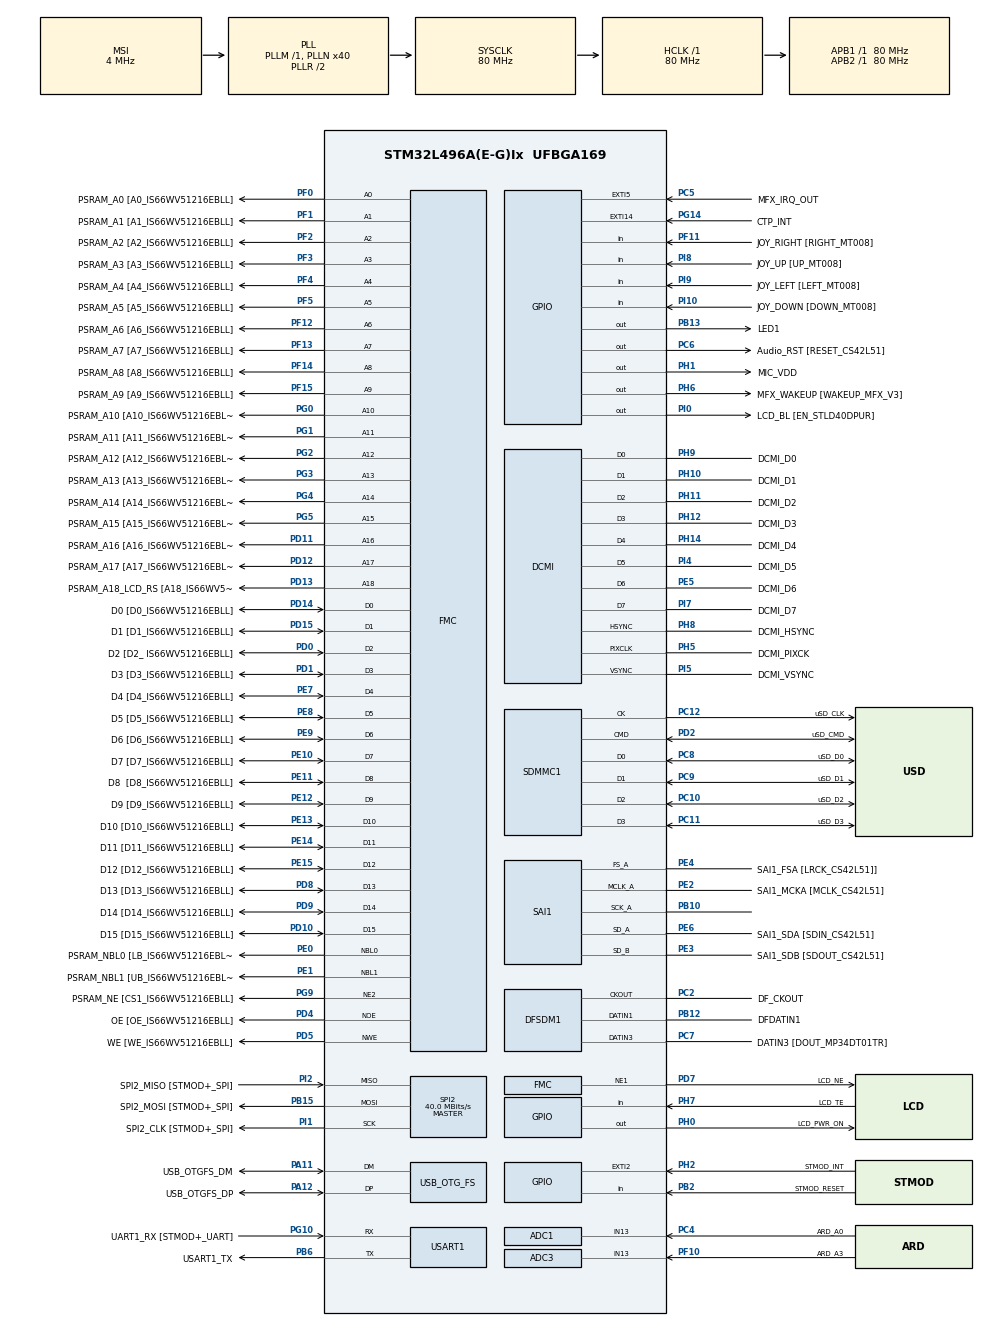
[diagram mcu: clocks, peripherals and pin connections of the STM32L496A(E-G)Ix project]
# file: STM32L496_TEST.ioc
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ADC1.Channel-0\#ChannelRegularConversion=ADC_CHANNEL_13
ADC1.NbrOfConversionFlag=1
ADC1.OffsetNumber-0\#ChannelRegularConversion=ADC_OFFSET_NONE
ADC1.Rank-0\#ChannelRegularConversion=1
ADC1.SamplingTime-0\#ChannelRegularConversion=ADC_SAMPLETIME_2CYCLES_5
ADC1.master=1
ADC3.Channel-0\#ChannelRegularConversion=ADC_CHANNEL_13
ADC3.NbrOfConversionFlag=1
ADC3.OffsetNumber-0\#ChannelRegularConversion=ADC_OFFSET_NONE
ADC3.Rank-0\#ChannelRegularConversion=1
ADC3.SamplingTime-0\#ChannelRegularConversion=ADC_SAMPLETIME_2CYCLES_5
ARM.CMSIS.5.8.0.CMSISJjCORE=true
ARM.CMSIS.5.8.0.CMSISJjDSP=Source
ARM.CMSIS.5.8.0.CMSISJjNNOoLib=true
DCMI.JPEGMode=DCMI_JPEG_DISABLE
Dma.Request0=SDMMC1_RX
Dma.Request1=SDMMC1_TX
Dma.SDMMC1_RX.0.Direction=DMA_PERIPH_TO_MEMORY
Dma.SDMMC1_RX.0.Instance=DMA2_Channel4
Dma.SDMMC1_RX.0.MemDataAlignment=DMA_MDATAALIGN_WORD
Dma.SDMMC1_RX.0.MemInc=DMA_MINC_ENABLE
Dma.SDMMC1_RX.0.Mode=DMA_NORMAL
Dma.SDMMC1_RX.0.PeriphDataAlignment=DMA_PDATAALIGN_WORD
Dma.SDMMC1_RX.0.PeriphInc=DMA_PINC_DISABLE
Dma.SDMMC1_RX.0.Priority=DMA_PRIORITY_LOW
Dma.SDMMC1_TX.1.Direction=DMA_MEMORY_TO_PERIPH
Dma.SDMMC1_TX.1.Instance=DMA2_Channel5
Dma.SDMMC1_TX.1.MemDataAlignment=DMA_MDATAALIGN_WORD
Dma.SDMMC1_TX.1.MemInc=DMA_MINC_ENABLE
Dma.SDMMC1_TX.1.Mode=DMA_NORMAL
Dma.SDMMC1_TX.1.PeriphDataAlignment=DMA_PDATAALIGN_WORD
Dma.SDMMC1_TX.1.PeriphInc=DMA_PINC_DISABLE
Dma.SDMMC1_TX.1.Priority=DMA_PRIORITY_LOW
FATFS.USE_DMA_CODE_SD=1
FATFS._USE_LFN=1
Mcu.Family=STM32L4
Mcu.Name=STM32L496A(E-G)Ix
Mcu.Package=UFBGA169
NVIC.DMA2_Channel4_IRQn=true\:5\:0\:true\:false\:true\:false\:true\:true
NVIC.DMA2_Channel5_IRQn=true\:5\:0\:true\:false\:true\:false\:true\:true
NVIC.OTG_FS_IRQn=true\:0\:0\:false\:false\:true\:true\:true\:true
NVIC.PriorityGroup=NVIC_PRIORITYGROUP_4
NVIC.SDMMC1_IRQn=true\:5\:0\:true\:false\:true\:true\:true\:true
NVIC.TIM5_IRQn=true\:0\:0\:false\:false\:true\:true\:true\:true
PA0.GPIO_Label=STMOD_PWM
PA0.Mode=SYS_WakeUp0
PA0.Signal=SYS_WKUP1
PA1.GPIO_Label=ARD_A4
PA1.Signal=ADCx_IN6
PA10.GPIO_Label=USB_OTGFS_ID
PA10.Signal=USB_OTG_FS_ID
PA11.GPIO_Label=USB_OTGFS_DM
PA11.Mode=Device_Only
PA11.Signal=USB_OTG_FS_DM
PA12.GPIO_Label=USB_OTGFS_DP
PA12.Mode=Device_Only
PA12.Signal=USB_OTG_FS_DP
PA13\ (JTMS/SWDIO).GPIO_Label=SWDIO
PA13\ (JTMS/SWDIO).Mode=Serial_Wire
PA13\ (JTMS/SWDIO).Signal=SYS_JTMS-SWDIO
PA14\ (JTCK/SWCLK).GPIO_Label=SWCLK
PA14\ (JTCK/SWCLK).Mode=Serial_Wire
PA14\ (JTCK/SWCLK).Signal=SYS_JTCK-SWCLK
PA15\ (JTDI).GPIO_Label=ARD_D10
PA15\ (JTDI).Signal=SPI1_NSS
PA2.GPIO_Label=USART2_TX
PA2.Signal=USART2_TX
PA3.GPIO_Label=QSPI_CLK [MX25R6435FM2IL0_SCLK]
PA3.Signal=QUADSPI_CLK
PA4.GPIO_Label=STMOD_ADC
PA4.Signal=ADCx_IN9
PA5.GPIO_Label=ARD_D13
PA5.Signal=SPI1_SCK
PA6.GPIO_Label=QSPI_BK1_IO3 [MX25R6435FM2IL0_SIO3]
PA6.Signal=QUADSPI_BK1_IO3
PA7.GPIO_Label=QSPI_BK1_IO2 [MX25R6435FM2IL0_SIO2]
PA7.Signal=QUADSPI_BK1_IO2
PA8.GPIO_Label=DCMI_CLK
PA8.Signal=LPTIM2_OUT
PA9.GPIO_Label=USB_OTGFS_VBUS
PA9.Signal=USB_OTG_FS_VBUS
PB0.GPIO_Label=QSPI_BK1_IO1 [MX25R6435FM2IL0_SIO1]
PB0.Signal=QUADSPI_BK1_IO1
PB1.GPIO_Label=QSPI_BK1_IO0 [MX25R6435FM2IL0_SIO0]
PB1.Signal=QUADSPI_BK1_IO0
PB10.Mode=SAI_A_MasterWithClock
PB10.Signal=SAI1_SCK_A
PB11.GPIO_Label=QSPI_BK1_NCS [MX25R6435FM2IL0_CS]
PB11.Signal=QUADSPI_BK1_NCS
PB12.GPIO_Label=DFDATIN1
PB12.Signal=S_DATAIN1DFSDM1
PB13.GPIO_Label=LED1
PB13.GPIO_ModeDefaultOutputPP=GPIO_MODE_OUTPUT_OD
PB13.GPIO_PuPd=GPIO_NOPULL
PB13.Signal=GPIO_Output
PB14.GPIO_Label=I2C2_SDA [CS42L51_SDA]
PB14.GPIO_Pu=GPIO_PULLUP
PB14.Signal=I2C2_SDA
PB15.GPIO_Label=SPI2_MOSI [STMOD+_SPI]
PB15.Mode=Full_Duplex_Master
PB15.Signal=SPI2_MOSI
PB2.GPIO_Label=STMOD_RESET
PB2.Signal=GPIO_Input
PB3\ (JTDO/TRACESWO).GPIO_Label=SWO
PB3\ (JTDO/TRACESWO).Signal=SYS_JTDO-SWO
PB4\ (NJTRST).GPIO_Label=ARD_D12
PB4\ (NJTRST).Signal=SPI1_MISO
PB5.GPIO_Label=ARD_D11
PB5.Signal=SPI1_MOSI
PB6.GPIO_Label=USART1_TX
PB6.Mode=Asynchronous
PB6.Signal=USART1_TX
PB7.GPIO_Label=I2C1_SDA
PB7.GPIO_Pu=GPIO_PULLUP
PB7.Signal=I2C1_SDA
PB8.GPIO_Label=I2C1_SCL
PB8.GPIO_Pu=GPIO_PULLUP
PB8.Signal=I2C1_SCL
PB9.GPIO_Label=ARD_D5
PB9.Signal=S_TIM4_CH4
PC0.GPIO_Label=ARD_A5
PC0.Signal=ADCx_IN1
PC1.Signal=ADCx_IN2
PC10.GPIO_Label=uSD_D2
PC10.GPIO_PuPd=GPIO_PULLUP
PC10.Mode=SD_4_bits_Wide_bus
PC10.Signal=SDMMC1_D2
PC11.GPIO_Label=uSD_D3
PC11.GPIO_PuPd=GPIO_PULLUP
PC11.Mode=SD_4_bits_Wide_bus
PC11.Signal=SDMMC1_D3
PC12.GPIO_Label=uSD_CLK
PC12.GPIO_PuPd=GPIO_PULLUP
PC12.Mode=SD_4_bits_Wide_bus
PC12.Signal=SDMMC1_CK
PC13.GPIO_Label=JOY_SEL [Selection_MT008]
PC13.Mode=SYS_WakeUp1
PC13.Signal=SYS_WKUP2
PC14-OSC32_IN\ (PC14).Mode=LSE-External-Clock-Source
PC14-OSC32_IN\ (PC14).Signal=RCC_OSC32_IN
PC15-OSC32_OUT\ (PC15).Signal=RCC_OSC32_OUT
PC2.GPIO_Label=DF_CKOUT
PC2.Signal=S_CKOUTDFSDM1
PC3.GPIO_Label=ARD_A2
PC3.Signal=ADCx_IN4
PC4.GPIO_Label=ARD_A0
PC4.Signal=ADCx_IN13
PC5.GPIO_Label=MFX_IRQ_OUT
PC5.Signal=GPXTI5
PC6.GPIO_Label=Audio_RST [RESET_CS42L51]
PC6.Signal=GPIO_Output
PC7.GPIO_Label=DATIN3 [DOUT_MP34DT01TR]
PC7.Signal=S_DATAIN3DFSDM1
PC8.GPIO_Label=uSD_D0
PC8.GPIO_PuPd=GPIO_PULLUP
PC8.Mode=SD_4_bits_Wide_bus
PC8.Signal=SDMMC1_D0
PC9.GPIO_Label=uSD_D1
PC9.GPIO_PuPd=GPIO_PULLUP
PC9.Mode=SD_4_bits_Wide_bus
PC9.Signal=SDMMC1_D1
PD0.GPIO_Label=D2 [D2_ IS66WV51216EBLL]
PD0.Signal=FMC_D2_DA2
PD1.GPIO_Label=D3 [D3_IS66WV51216EBLL]
PD1.Signal=FMC_D3_DA3
PD10.GPIO_Label=D15 [D15_IS66WV51216EBLL]
PD10.Signal=FMC_D15_DA15
PD11.GPIO_Label=PSRAM_A16 [A16_IS66WV51216EBLL]
PD11.Signal=FMC_A16_CLE
PD12.GPIO_Label=PSRAM_A17 [A17_IS66WV51216EBLL]
PD12.Signal=FMC_A17_ALE
PD13.GPIO_Label=PSRAM_A18_LCD_RS [A18_IS66WV51216EBLL]
PD13.Signal=FMC_A18
PD14.GPIO_Label=D0 [D0_IS66WV51216EBLL]
PD14.Signal=FMC_D0_DA0
PD15.GPIO_Label=D1 [D1_IS66WV51216EBLL]
PD15.Signal=FMC_D1_DA1
PD2.GPIO_Label=uSD_CMD
PD2.GPIO_PuPd=GPIO_PULLUP
PD2.Mode=SD_4_bits_Wide_bus
PD2.Signal=SDMMC1_CMD
PD4.GPIO_Label=OE [OE_IS66WV51216EBLL]
PD4.Signal=FMC_NOE
PD5.GPIO_Label=WE [WE_IS66WV51216EBLL]
PD5.Signal=FMC_NWE
PD6.GPIO_Label=USART2_RX
PD6.Signal=USART2_RX
PD7.GPIO_Label=LCD_NE
PD7.Mode=NorPsramChipSelect1_2
PD7.Signal=FMC_NE1
PD8.GPIO_Label=D13 [D13_IS66WV51216EBLL]
PD8.Signal=FMC_D13_DA13
PD9.GPIO_Label=D14 [D14_IS66WV51216EBLL]
PD9.Signal=FMC_D14_DA14
PE0.GPIO_Label=PSRAM_NBL0 [LB_IS66WV51216EBLL]
PE0.Signal=FMC_NBL0
PE1.GPIO_Label=PSRAM_NBL1 [UB_IS66WV51216EBLL]
PE1.Signal=FMC_NBL1
PE10.GPIO_Label=D7 [D7_IS66WV51216EBLL]
PE10.Signal=FMC_D7_DA7
PE11.GPIO_Label=D8  [D8_IS66WV51216EBLL]
PE11.Signal=FMC_D8_DA8
PE12.GPIO_Label=D9 [D9_IS66WV51216EBLL]
PE12.Signal=FMC_D9_DA9
PE13.GPIO_Label=D10 [D10_IS66WV51216EBLL]
PE13.Signal=FMC_D10_DA10
PE14.GPIO_Label=D11 [D11_IS66WV51216EBLL]
PE14.Signal=FMC_D11_DA11
PE15.GPIO_Label=D12 [D12_IS66WV51216EBLL]
PE15.Signal=FMC_D12_DA12
PE2.GPIO_Label=SAI1_MCKA [MCLK_CS42L51]
PE2.Mode=SAI_A_MasterWithClock
PE2.Signal=SAI1_MCLK_A
PE3.GPIO_Label=SAI1_SDB [SDOUT_CS42L51]
PE3.Mode=SAI_B_SyncSlave
PE3.Signal=SAI1_SD_B
PE4.GPIO_Label=SAI1_FSA [LRCK_CS42L51]]
PE4.Mode=SAI_A_MasterWithClock
PE4.Signal=SAI1_FS_A
PE5.GPIO_Label=DCMI_D6
PE5.Mode=Slave_8_bits_External_Synchro
PE5.Signal=DCMI_D6
PE6.GPIO_Label=SAI1_SDA [SDIN_CS42L51]
PE6.Mode=SAI_A_MasterWithClock
PE6.Signal=SAI1_SD_A
PE7.GPIO_Label=D4 [D4_IS66WV51216EBLL]
PE7.Signal=FMC_D4_DA4
PE8.GPIO_Label=D5 [D5_IS66WV51216EBLL]
PE8.Signal=FMC_D5_DA5
PE9.GPIO_Label=D6 [D6_IS66WV51216EBLL]
PE9.Signal=FMC_D6_DA6
PF0.GPIO_Label=PSRAM_A0 [A0_IS66WV51216EBLL]
PF0.Signal=FMC_A0
PF1.GPIO_Label=PSRAM_A1 [A1_IS66WV51216EBLL]
PF1.Signal=FMC_A1
PF10.GPIO_Label=ARD_A3
PF10.Mode=IN13-Single-Ended
PF10.Signal=ADC3_IN13
PF11.GPIO_Label=JOY_RIGHT [RIGHT_MT008]
PF11.GPIO_PuPd=GPIO_PULLDOWN
PF11.Signal=GPIO_Input
PF12.GPIO_Label=PSRAM_A6 [A6_IS66WV51216EBLL]
PF12.Signal=FMC_A6
PF13.GPIO_Label=PSRAM_A7 [A7_IS66WV51216EBLL]
PF13.Signal=FMC_A7
PF14.GPIO_Label=PSRAM_A8 [A8_IS66WV51216EBLL]
PF14.Signal=FMC_A8
PF15.GPIO_Label=PSRAM_A9 [A9_IS66WV51216EBLL]
PF15.Signal=FMC_A9
PF2.GPIO_Label=PSRAM_A2 [A2_IS66WV51216EBLL]
PF2.Signal=FMC_A2
PF3.GPIO_Label=PSRAM_A3 [A3_IS66WV51216EBLL]
PF3.Signal=FMC_A3
PF4.GPIO_Label=PSRAM_A4 [A4_IS66WV51216EBLL]
PF4.Signal=FMC_A4
PF5.GPIO_Label=PSRAM_A5 [A5_IS66WV51216EBLL]
PF5.Signal=FMC_A5
PG0.GPIO_Label=PSRAM_A10 [A10_IS66WV51216EBLL]
PG0.Signal=FMC_A10
PG1.GPIO_Label=PSRAM_A11 [A11_IS66WV51216EBLL]
PG1.Signal=FMC_A11
PG10.GPIO_Label=UART1_RX [STMOD+_UART]
PG10.Mode=Asynchronous
PG10.Signal=USART1_RX
PG11.GPIO_Label=UART1_CTS [STMOD+_UART]
PG11.Signal=USART1_CTS
PG12.GPIO_Label=UART1_RTS [STMOD+_UART]
PG12.Signal=USART1_RTS
PG14.GPIO_Label=CTP_INT
PG14.Signal=GPXTI14
PG2.GPIO_Label=PSRAM_A12 [A12_IS66WV51216EBLL]
PG2.Signal=FMC_A12
PG3.GPIO_Label=PSRAM_A13 [A13_IS66WV51216EBLL]
PG3.Signal=FMC_A13
PG4.GPIO_Label=PSRAM_A14 [A14_IS66WV51216EBLL]
PG4.Signal=FMC_A14
PG5.GPIO_Label=PSRAM_A15 [A15_IS66WV51216EBLL]
PG5.Signal=FMC_A15
PG7.GPIO_Label=ARD_D1
PG7.Signal=LPUART1_TX
PG8.GPIO_Label=ARD_D0
PG8.Signal=LPUART1_RX
PG9.GPIO_Label=PSRAM_NE [CS1_IS66WV51216EBLL]
PG9.Mode=NorPsramChipSelect2_1
PG9.Signal=FMC_NE2
PH0-OSC_IN\ (PH0).GPIO_Label=LCD_PWR_ON
PH0-OSC_IN\ (PH0).Signal=GPIO_Output
PH1-OSC_OUT\ (PH1).GPIO_Label=MIC_VDD
PH1-OSC_OUT\ (PH1).Signal=GPIO_Output
PH10.GPIO_Label=DCMI_D1
PH10.Mode=Slave_8_bits_External_Synchro
PH10.Signal=DCMI_D1
PH11.GPIO_Label=DCMI_D2
PH11.Mode=Slave_8_bits_External_Synchro
PH11.Signal=DCMI_D2
PH12.GPIO_Label=DCMI_D3
PH12.Mode=Slave_8_bits_External_Synchro
PH12.Signal=DCMI_D3
PH13.GPIO_Label=ARD_D9
PH13.Signal=TIM8_CH1N
PH14.GPIO_Label=DCMI_D4
PH14.Mode=Slave_8_bits_External_Synchro
PH14.Signal=DCMI_D4
PH15.GPIO_Label=ARD_D3
PH15.Signal=TIM8_CH3N
PH2.GPIO_Label=STMOD_INT
PH2.Signal=GPXTI2
PH4.GPIO_Label=I2C2_SCL [SCL_CS42L51]
PH4.GPIO_Pu=GPIO_PULLUP
PH4.Signal=I2C2_SCL
PH5.GPIO_Label=DCMI_PIXCK
PH5.Mode=Slave_8_bits_External_Synchro
PH5.Signal=DCMI_PIXCLK
PH6.GPIO_Label=MFX_WAKEUP [WAKEUP_MFX_V3]
PH6.Signal=GPIO_Output
PH7.GPIO_Label=LCD_TE
PH7.Signal=GPIO_Input
PH8.GPIO_Label=DCMI_HSYNC
PH8.Mode=Slave_8_bits_External_Synchro
PH8.Signal=DCMI_HSYNC
PH9.GPIO_Label=DCMI_D0
PH9.Mode=Slave_8_bits_External_Synchro
PH9.Signal=DCMI_D0
PI0.GPIO_Label=LCD_BL [EN_STLD40DPUR]
PI0.Signal=GPIO_Output
PI1.GPIO_Label=SPI2_CLK [STMOD+_SPI]
PI1.Mode=Full_Duplex_Master
PI1.Signal=SPI2_SCK
PI10.GPIO_Label=JOY_DOWN [DOWN_MT008]
PI10.GPIO_PuPd=GPIO_PULLDOWN
PI10.Signal=GPIO_Input
PI2.GPIO_Label=SPI2_MISO [STMOD+_SPI]
PI2.Mode=Full_Duplex_Master
PI2.Signal=SPI2_MISO
PI4.GPIO_Label=DCMI_D5
PI4.Mode=Slave_8_bits_External_Synchro
PI4.Signal=DCMI_D5
PI5.GPIO_Label=DCMI_VSYNC
PI5.Mode=Slave_8_bits_External_Synchro
PI5.Signal=DCMI_VSYNC
PI6.GPIO_Label=ARD_D6
PI6.Signal=S_TIM8_CH2
PI7.GPIO_Label=DCMI_D7
PI7.Mode=Slave_8_bits_External_Synchro
PI7.Signal=DCMI_D7
PI8.GPIO_Label=JOY_UP [UP_MT008]
PI8.GPIO_PuPd=GPIO_PULLDOWN
PI8.Signal=GPIO_Input
PI9.GPIO_Label=JOY_LEFT [LEFT_MT008]
PI9.GPIO_PuPd=GPIO_PULLDOWN
PI9.Signal=GPIO_Input
ProjectManager.HeapSize=0x200
ProjectManager.StackSize=0x400
ProjectManager.TargetToolchain=STM32CubeIDE
RCC.ADCFreq_Value=48000000
RCC.AHBFreq_Value=80000000
RCC.APB1Freq_Value=80000000
RCC.APB1TimFreq_Value=80000000
RCC.APB2Freq_Value=80000000
RCC.APB2TimFreq_Value=80000000
RCC.CortexFreq_Value=80000000
RCC.HCLKFreq_Value=80000000
RCC.HSE_VALUE=8000000
RCC.HSI48_VALUE=48000000
RCC.HSI_VALUE=16000000
RCC.MSI_VALUE=4000000
RCC.PLLN=40
RCC.PLLSAI1N=24
RCC.SYSCLKFreq_VALUE=80000000
RCC.SYSCLKSource=RCC_SYSCLKSOURCE_PLLCLK
RCC.USBFreq_Value=48000000
RCC.VCOOutputFreq_Value=160000000
SAI1.ErrorAudioFreq-SAI_A_MasterWithClock=-2.34 %
SAI1.Instance-SAI_A_MasterWithClock=SAI$Index_Block_A
SAI1.Instance-SAI_B_SyncSlave=SAI$Index_Block_B
SAI1.MClockEnable-SAI_A_MasterWithClock=SAI_MASTERCLOCK_ENABLE
SAI1.RealAudioFreq-SAI_A_MasterWithClock=187.5 KHz
SAI1.VirtualMode-SAI_A_MasterWithClock=VM_MASTER
SAI1.VirtualMode-SAI_B_SyncSlave=VM_SLAVE
SH.ADCx_IN1.0=ADC2_IN1
SH.ADCx_IN13.0=ADC1_IN13,IN13-Single-Ended
SH.ADCx_IN2.0=ADC2_IN2
SH.ADCx_IN4.0=ADC1_IN4
SH.ADCx_IN6.0=ADC2_IN6
SH.ADCx_IN9.0=ADC2_IN9
SH.FMC_A0.0=FMC_A0,18b-a1
SH.FMC_A1.0=FMC_A1,18b-a1
SH.FMC_A10.0=FMC_A10,18b-a1
SH.FMC_A11.0=FMC_A11,18b-a1
SH.FMC_A12.0=FMC_A12,18b-a1
SH.FMC_A13.0=FMC_A13,18b-a1
SH.FMC_A14.0=FMC_A14,18b-a1
SH.FMC_A15.0=FMC_A15,18b-a1
SH.FMC_A16_CLE.0=FMC_A16,18b-a1
SH.FMC_A17_ALE.0=FMC_A17,18b-a1
SH.FMC_A18.0=FMC_A18,A18_2
SH.FMC_A2.0=FMC_A2,18b-a1
SH.FMC_A3.0=FMC_A3,18b-a1
SH.FMC_A4.0=FMC_A4,18b-a1
SH.FMC_A5.0=FMC_A5,18b-a1
SH.FMC_A6.0=FMC_A6,18b-a1
SH.FMC_A7.0=FMC_A7,18b-a1
SH.FMC_A8.0=FMC_A8,18b-a1
SH.FMC_A9.0=FMC_A9,18b-a1
SH.FMC_D0_DA0.0=FMC_D0,16b-d1
SH.FMC_D0_DA0.1=FMC_D0,16b-d2
SH.FMC_D10_DA10.0=FMC_D10,16b-d1
SH.FMC_D10_DA10.1=FMC_D10,16b-d2
SH.FMC_D11_DA11.0=FMC_D11,16b-d1
SH.FMC_D11_DA11.1=FMC_D11,16b-d2
SH.FMC_D12_DA12.0=FMC_D12,16b-d1
SH.FMC_D12_DA12.1=FMC_D12,16b-d2
SH.FMC_D13_DA13.0=FMC_D13,16b-d1
SH.FMC_D13_DA13.1=FMC_D13,16b-d2
SH.FMC_D14_DA14.0=FMC_D14,16b-d1
SH.FMC_D14_DA14.1=FMC_D14,16b-d2
SH.FMC_D15_DA15.0=FMC_D15,16b-d1
SH.FMC_D15_DA15.1=FMC_D15,16b-d2
SH.FMC_D1_DA1.0=FMC_D1,16b-d1
SH.FMC_D1_DA1.1=FMC_D1,16b-d2
SH.FMC_D2_DA2.0=FMC_D2,16b-d1
SH.FMC_D2_DA2.1=FMC_D2,16b-d2
SH.FMC_D3_DA3.0=FMC_D3,16b-d1
SH.FMC_D3_DA3.1=FMC_D3,16b-d2
SH.FMC_D4_DA4.0=FMC_D4,16b-d1
SH.FMC_D4_DA4.1=FMC_D4,16b-d2
SH.FMC_D5_DA5.0=FMC_D5,16b-d1
SH.FMC_D5_DA5.1=FMC_D5,16b-d2
SH.FMC_D6_DA6.0=FMC_D6,16b-d1
SH.FMC_D6_DA6.1=FMC_D6,16b-d2
SH.FMC_D7_DA7.0=FMC_D7,16b-d1
SH.FMC_D7_DA7.1=FMC_D7,16b-d2
SH.FMC_D8_DA8.0=FMC_D8,16b-d1
SH.FMC_D8_DA8.1=FMC_D8,16b-d2
SH.FMC_D9_DA9.0=FMC_D9,16b-d1
SH.FMC_D9_DA9.1=FMC_D9,16b-d2
SH.FMC_NBL0.0=FMC_NBL0,2ByteEnable1
SH.FMC_NBL1.0=FMC_NBL1,2ByteEnable1
SH.FMC_NOE.0=FMC_NOE,Sram1
SH.FMC_NOE.1=FMC_NOE,Lcd2
SH.FMC_NWE.0=FMC_NWE,Sram1
SH.FMC_NWE.1=FMC_NWE,Lcd2
SH.S_CKOUTDFSDM1.0=DFSDM1_CKOUT,PDM_SPI_Input_from_ch23_and_Internal_Clock
SH.S_CKOUTDFSDM1.1=DFSDM1_CKOUT,PDM_SPI_input_from_ch1_and_internal_clock
SH.S_DATAIN1DFSDM1.0=DFSDM1_DATIN1,PDM_SPI_input_from_ch1_and_internal_clock
SH.S_DATAIN3DFSDM1.0=DFSDM1_DATIN3,PDM_SPI_Input_from_ch23_and_Internal_Clock
SH.S_TIM4_CH4.0=TIM4_CH4
SH.S_TIM8_CH2.0=TIM8_CH2
SPI2.CalculateBaudRate=40.0 MBits/s
SPI2.Direction=SPI_DIRECTION_2LINES
SPI2.Mode=SPI_MODE_MASTER
SPI2.VirtualType=VM_MASTER
TIM5.Period=0xffffffff-1
TIM5.Prescaler=1-1
TIM6.Period=65536-1
TIM6.Prescaler=80-1
USART1.VirtualMode-Asynchronous=VM_ASYNC
USB_DEVICE.CLASS_NAME_FS=CDC
USB_DEVICE.VirtualMode=Cdc
USB_DEVICE.VirtualModeFS=Cdc_FS
USB_OTG_FS.VirtualMode=Device_Only
VP_ARM.CMSIS_VS_CMSISJjCORE_5.5.0_5.8.0.Mode=CMSISJjCORE
VP_ARM.CMSIS_VS_CMSISJjDSP_1.9.0-dev_5.8.0.Mode=CMSISJjDSP
VP_ARM.CMSIS_VS_CMSISJjNNOoLib_3.0.0_5.8.0.Mode=CMSISJjNNOoLib
VP_FATFS_VS_SDIO.Mode=SDIO
VP_TIM5_VS_ClockSourceINT.Mode=Internal
VP_TIM6_VS_ClockSourceINT.Mode=Enable_Timer
VP_USB_DEVICE_VS_USB_DEVICE_CDC_FS.Mode=CDC_FS
board=STM32L496G-DISCO

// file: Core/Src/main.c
/* USER CODE BEGIN Header */
/**
  ******************************************************************************
  * @file           : main.c
  * @brief          : Main program body
  ******************************************************************************
  * @attention
  *
  * Copyright (c) 2023 STMicroelectronics.
  * All rights reserved.
  *
  * This software is licensed under terms that can be found in the LICENSE file
  * in the root directory of this software component.
  * If no LICENSE file comes with this software, it is provided AS-IS.
  *
  ******************************************************************************
  */
/* USER CODE END Header */
#include "main.h"
#include "fatfs.h"
#include "usb_device.h"

/* USER CODE BEGIN Includes */
#include <stdint.h>
#include <stdlib.h>
#include <stdio.h>
#include <assert.h>

#include "nnom.h"
#include "weights.h"
/* USER CODE END Includes */

/* USER CODE BEGIN PD */
extern volatile uint64_t SysTickCnt;
extern volatile uint64_t SysTickCnt1;
extern volatile uint64_t SysTickCnt2;
uint64_t TimerDelay=0;
uint64_t TimerCount;
uint64_t TimerCountSec;
//extern volatile uint64_t us_SysTickCnt;
//extern volatile uint64_t us_SysTickCnt1;
/* USER CODE END PD */

ADC_HandleTypeDef hadc1;
ADC_HandleTypeDef hadc3;

DCMI_HandleTypeDef hdcmi;

DFSDM_Channel_HandleTypeDef hdfsdm1_channel1;
DFSDM_Channel_HandleTypeDef hdfsdm1_channel2;

SAI_HandleTypeDef hsai_BlockA1;
SAI_HandleTypeDef hsai_BlockB1;

SD_HandleTypeDef hsd1;
DMA_HandleTypeDef hdma_sdmmc1_rx;
DMA_HandleTypeDef hdma_sdmmc1_tx;

SPI_HandleTypeDef hspi2;

TIM_HandleTypeDef htim5;
TIM_HandleTypeDef htim6;

UART_HandleTypeDef huart1;

SRAM_HandleTypeDef hsram1;
SRAM_HandleTypeDef hsram2;

/* USER CODE BEGIN PV */
//void f_opendir_scan(void);
/* USER CODE END PV */

void SystemClock_Config(void);
void PeriphCommonClock_Config(void);
static void MX_GPIO_Init(void);
static void MX_DMA_Init(void);
static void MX_ADC1_Init(void);
static void MX_ADC3_Init(void);
static void MX_DCMI_Init(void);
static void MX_DFSDM1_Init(void);
static void MX_FMC_Init(void);
static void MX_USART1_UART_Init(void);
static void MX_SAI1_Init(void);
static void MX_SDMMC1_SD_Init(void);
static void MX_SPI2_Init(void);
static void MX_TIM6_Init(void);
static void MX_TIM5_Init(void);

/* USER CODE BEGIN 0 */
/*
void HAL_TIM_PeriodElapsedCallback(TIM_HandleTypeDef *htim)
{

	if(htim->Instance == TIM6)
	{
		if(TimerCount < 5000000)
		{
			TimerCount++;
		}
		else
		{
#if 0
			if(TimerCountSec < 60)
			{
				TimerCountSec++;
			}
			else
			{
				TimerCountSec=0;
			}
#endif
			TimerCount=0;
		}
	}
}
*/
int8_t* load(const char* file, size_t * size)
{
	size_t sz;
	FILE* fp = fopen(file,"rb");
	int8_t* input;
	assert(fp);
	fseek(fp, 0, SEEK_END);
	sz = ftell(fp);
	fseek(fp, 0, SEEK_SET);
	input = malloc(sz);
	fread(input, 1, sz, fp);
	fclose(fp);
	*size = sz;
	return input;
}

nnom_status_t callback(nnom_model_t* m, nnom_layer_t* layer)
{
	float scale = 1 << (layer->out->tensor->q_dec[0]);
	printf("\nOutput of Layer %s", default_layer_names[layer->type]);
	for (int i = 0; i < tensor_size(layer->out->tensor); i++)
	{
		if (i % 16 == 0)
			printf("\n");
		//printf("%f ", (float)((int8_t*)layer->out->tensor->p_data)[i] / scale);
	}
	printf("\n");
	return NN_SUCCESS;
}

/* USER CODE END 0 */

int main(void)
{
  /* USER CODE BEGIN 1 */
	uint64_t sine_input_data[400]=
			{
			 2.08695419, 0.76689931, 4.74582312, 5.05426909, 6.25972379, 5.17592351,
			 5.04563954, 2.70270019, 3.99913156, 5.98756371, 1.19539429, 3.28134257,
			 4.83127744, 3.65830856, 2.56685459, 5.54898327, 0.08833249, 0.56087708,
			 0.52861911, 5.09026597, 2.44528008, 5.73465215, 6.11904136, 2.80423079,
			 3.14940047, 3.63168313, 5.6821393,  0.57851344, 4.07710848, 3.54048319,
			 3.11324864, 2.10204613, 3.87680897, 0.19928605, 2.69465816, 0.22969943,
			 3.2490809, 3.7164528,  3.43202967, 2.04771038, 4.71435523, 3.12718626,
			 5.99622483, 6.26340629, 0.73648756, 0.780399,   6.02199553, 5.87205802,
			 4.45601254, 5.06354697, 4.78286746, 4.72836316, 1.59432706, 5.40692325,
			 1.22285658, 4.09214892, 4.64688536, 0.69933188, 5.71745025, 2.20655855,
			 4.33961395, 3.12272388, 4.72167151, 3.7150221,  5.6648941,  5.46039667,
			 2.77459441, 0.550436,   1.53303783, 3.52287725, 4.0653286,  4.36009327,
			 0.34010971, 2.44585525, 1.0348866,  5.33742292, 3.32143552, 3.33726546,
			 3.49536546, 2.24441524, 5.1390628,  5.49069287, 2.42088815, 0.90763034,
			 6.23429342, 0.15590885, 1.62910138, 3.14691749, 0.19715427, 0.42467694,
			 0.724386,   0.17056014, 3.29771079, 2.76921085, 1.62946275, 5.16783221,
			 0.80726899, 5.2280378,  1.81096906, 5.94610609, 4.84921627, 2.87473706,
			 5.8737587,  3.86788732, 1.2601702,  3.75132209, 1.24127618, 5.3913218,
			 1.5498286,  1.91143653, 0.63133646, 4.99938901, 0.49256017, 0.04035357,
			 5.6022348,  4.92948964, 5.65896911, 2.54951337, 2.67772437, 1.41867595,
			 3.99107708, 5.88654158, 3.88043218, 1.73779883, 5.10445431, 4.71479072,
			 0.73709591, 2.890005,   5.82162277, 0.24970332, 1.46252155, 5.29140275,
			 1.00074824, 3.01055499, 4.72678514, 3.32773414, 2.68666938, 4.46329594,
			 1.74474435, 2.29807342, 1.98501637, 2.46272018, 1.6153572,  2.59601391,
			 3.46666425, 5.63477438, 5.38232322, 1.67568923, 4.90026508, 1.75509981,
			 0.8844397,  5.73421103, 3.00028104, 3.31121815, 3.40114173, 0.2158798,
			 4.21723394, 3.0450399,  5.0505918,  4.07993413, 5.76991797, 0.03692868,
			 1.78871852, 2.06750289, 6.17315554, 0.41259688, 6.27580458, 3.31359511,
			 0.75584901, 0.77755006, 4.60445792, 2.79901728, 4.89211283, 4.51065309,
			 5.9556905,  1.04764683, 5.9245,     6.09746461, 0.67397198, 1.1175135,
			 0.27154077, 5.11226692, 0.95974585, 3.99382931, 3.01374228, 4.43766436,
			 4.9349161,  1.8536068,  2.81799255, 3.86591664, 3.71580724, 3.85324266,
			 3.65884674, 1.09280759, 3.51361338, 3.43296269, 0.276919,   0.70406377,
			 2.0265911,  1.23010984, 5.8723954,  5.57306316, 5.96544788, 4.5161241,
			 0.38560253, 1.05943098, 0.69713181, 1.35469022, 6.18105899, 5.50940501,
			 1.30293693, 0.5740297,  3.16573378, 1.52456956, 5.856283,   1.44380873,
			 4.58958354, 2.75357767, 3.38436842, 0.50722714, 5.65793132, 5.36222335,
			 4.29809155, 3.77912918, 5.0750548,  2.1628121,  0.46299865, 5.4858977,
			 4.07345295, 2.74685508, 3.22548635, 4.1514482,  0.03282755, 4.29765143,
			 1.11005891, 5.53483601, 3.20034811, 4.43732275, 5.54329779, 5.09172381,
			 1.87488243, 2.40444571, 2.77523744, 1.88837785, 0.35725745, 1.9903032,
			 1.98847203, 5.15257429, 5.23198119, 4.01861693, 1.01494732, 4.58564252,
			 5.49813942, 1.44230306, 3.3950008,  4.5575466,  2.1262126,  0.18657707,
			 1.80067403, 1.75972771, 2.40092871, 5.27486983, 3.62027504, 0.94121215,
			 4.24400976, 5.71093421, 3.33695234, 4.69042588, 4.6679446,  2.22999369,
			 3.04629233, 5.05546414, 6.23539512, 6.12784717, 4.76898606, 3.40453647,
			 4.18971958, 3.45977306, 5.33601224, 3.04373973, 2.09230867, 3.3597323,
			 4.2758165,  0.32494225, 1.08188177, 4.83807308, 6.12270297, 1.63917385,
			 0.05754941, 2.75779713, 2.56369735, 5.87874567, 0.11481112, 4.71573081,
			 1.06660722, 4.6480726,  2.1956989,  4.01952579, 5.18644456, 1.73525091,
			 4.13652427, 3.29216507, 1.81250605, 0.56569308, 2.27930236, 4.63858324,
			 5.96000597, 2.89179211, 4.88844215, 5.02268595, 5.85444001, 0.69439757,
			 5.05325718, 4.01808686, 1.11056002, 1.31843526, 3.92501732, 2.8849584,
			 3.78206903, 4.35851701, 4.55138129, 2.79028265, 3.12955137, 0.99998988,
			 1.28558634, 1.09003759, 5.35965953, 0.0670564,  0.37559138, 5.6332237,
			 1.6602608,  5.45714994, 1.88564882, 2.15390808, 2.50313823, 2.17726969,
			 3.2858739,  2.6412539,  2.29335861, 0.49016144, 3.64283181, 5.0059637,
			 4.07754492, 3.40703553, 3.8940697,  0.24084188, 2.5357001, 2.88979379,
			 3.09579139, 1.68811179, 1.19372458, 5.43472717, 0.16966966, 3.81456796,
			 1.43662181, 1.80431179, 2.01450516, 5.32662936, 1.46671327, 1.87310498,
			 0.88970747, 2.14186225, 3.22437468, 5.90339597, 2.29966888, 4.36749354,
			 0.26064666, 4.34127616, 4.18827682, 0.73445369, 0.1509077,  1.00256865,
			 4.99012329, 2.16234692, 2.3329883,  1.53013353, 4.43697189, 2.87249533,
			 3.96619262, 1.56197448, 0.70853612, 4.49769003, 4.17144703, 5.8445012,
			 3.89486767, 0.02230128, 2.61849801, 6.16805925, 5.07065454, 2.17824695,
			 1.90748733, 5.54388068, 3.9275137,  3.29888327, 6.24196832, 1.98646822,
			 2.14897505, 2.20384449, 3.55629195, 2.24916268};

	unsigned char input_data_third[7968] =
	{
			7,	2,	1,	0,	4,	1,	4,	9,	5,	9,	0,	6,	9,	0,	1,	5,	0,	0,	0,	0,	0,	0,	0,	0,	0,	0,	0,	0,
			0,	0,	0,	0,	0,	0,	0,	0,	0,	0,	0,	0,	0,	0,	0,	0,	0,	0,	0,	0,	0,	0,	0,	0,	0,	0,	0,	0,
			0,	0,	0,	0,	0,	0,	0,	0,	0,	0,	0,	0,	0,	0,	0,	0,	0,	0,	0,	0,	0,	0,	0,	0,	0,	0,	0,	0,
			0,	0,	0,	0,	0,	0,	0,	0,	0,	0,	0,	0,	0,	0,	0,	0,	0,	0,	0,	0,	0,	0,	0,	0,	0,	0,	0,	0,
			0,	0,	0,	0,	0,	0,	0,	0,	0,	0,	0,	0,	0,	0,	0,	0,

			0,	0,	0,	0,	0,	0,	0,	0,	0,	0,	0,	0,	0,	0,	0,	0,	0,	0,	0,	0,	0,	0,	0,	0,	0,	0,	0,	0,
			0,	0,	0,	0,	0,	0,	0,	0,	0,	0,	0,	0,	0,	0,	0,	0,	0,	0,	0,	0,	0,	0,	0,	0,	0,	0,	0,	0,
			0,	0,	0,	0,	0,	0,	0,	0,	0,	0,	0,	0,	0,	0,	0,	0,	0,	0,	0,	0,	0,	0,	0,	0,	0,	0,	0,	0,
			0,	0,	0,	0,	0,	0,	0,	0,	0,	0,	0,	0,	0,	0,	0,	0,	0,	0,	0,	0,	0,	0,	0,	0,	0,	0,	0,	0,
			0,	0,	0,	0,	0,	0,	0,	0,	0,	0,	0,	0,	0,	0,	0,	0,	0,	0,	0,	0,	0,	0,	0,	0,	0,	0,	0,	0,
			0,	0,	0,	0,	0,	0,	0,	0,	0,	0,	0,	0,	0,	0,	0,	0,	0,	0,	0,	0,	0,	0,	0,	0,	0,	0,	0,	0,
			0,	0,	0,	0,	0,	0,	0,	0,	0,	0,	0,	0,	0,	0,	0,	0,	0,	0,	0,	0,	0,	0,	0,	0,	0,	0,	0,	0,
			0,	0,	0,	0,	0,	0,	42,	92,	79,	75,	30,	18,	0,	0,	0,	0,	0,	0,	0,	0,	0,	0,	0,	0,	0,	0,	0,	0,
			0,	0,	0,	0,	0,	0,	111,	127,	127,	127,	127,	120,	99,	99,	99,	99,	99,	99,	99,	99,	85,	26,	0,	0,	0,	0,	0,	0,
			0,	0,	0,	0,	0,	0,	33,	57,	36,	57,	81,	113,	127,	112,	127,	127,	127,	125,	114,	127,	127,	70,	0,	0,	0,	0,	0,	0,
			0,	0,	0,	0,	0,	0,	0,	0,	0,	0,	0,	8,	33,	7,	33,	33,	33,	29,	10,	118,	127,	53,	0,	0,	0,	0,	0,	0,
			0,	0,	0,	0,	0,	0,	0,	0,	0,	0,	0,	0,	0,	0,	0,	0,	0,	0,	41,	126,	104,	9,	0,	0,	0,	0,	0,	0,
			0,	0,	0,	0,	0,	0,	0,	0,	0,	0,	0,	0,	0,	0,	0,	0,	0,	11,	116,	127,	41,	0,	0,	0,	0,	0,	0,	0,
			0,	0,	0,	0,	0,	0,	0,	0,	0,	0,	0,	0,	0,	0,	0,	0,	0,	64,	127,	119,	22,	0,	0,	0,	0,	0,	0,	0,
			0,	0,	0,	0,	0,	0,	0,	0,	0,	0,	0,	0,	0,	0,	0,	0,	29,	124,	127,	31,	0,	0,	0,	0,	0,	0,	0,	0,
			0,	0,	0,	0,	0,	0,	0,	0,	0,	0,	0,	0,	0,	0,	0,	0,	66,	127,	93,	2,	0,	0,	0,	0,	0,	0,	0,	0,
			0,	0,	0,	0,	0,	0,	0,	0,	0,	0,	0,	0,	0,	0,	0,	4,	102,	124,	29,	0,	0,	0,	0,	0,	0,	0,	0,	0,
			0,	0,	0,	0,	0,	0,	0,	0,	0,	0,	0,	0,	0,	0,	0,	63,	127,	91,	0,	0,	0,	0,	0,	0,	0,	0,	0,	0,
			0,	0,	0,	0,	0,	0,	0,	0,	0,	0,	0,	0,	0,	0,	37,	125,	120,	28,	0,	0,	0,	0,	0,	0,	0,	0,	0,	0,
			0,	0,	0,	0,	0,	0,	0,	0,	0,	0,	0,	0,	0,	9,	110,	127,	83,	0,	0,	0,	0,	0,	0,	0,	0,	0,	0,	0,
			0,	0,	0,	0,	0,	0,	0,	0,	0,	0,	0,	0,	1,	101,	127,	109,	17,	0,	0,	0,	0,	0,	0,	0,	0,	0,	0,	0,
			0,	0,	0,	0,	0,	0,	0,	0,	0,	0,	0,	0,	19,	127,	127,	38,	0,	0,	0,	0,	0,	0,	0,	0,	0,	0,	0,	0,
			0,	0,	0,	0,	0,	0,	0,	0,	0,	0,	0,	15,	112,	127,	57,	0,	0,	0,	0,	0,	0,	0,	0,	0,	0,	0,	0,	0,
			0,	0,	0,	0,	0,	0,	0,	0,	0,	0,	0,	66,	127,	127,	26,	0,	0,	0,	0,	0,	0,	0,	0,	0,	0,	0,	0,	0,
			0,	0,	0,	0,	0,	0,	0,	0,	0,	0,	30,	121,	127,	127,	26,	0,	0,	0,	0,	0,	0,	0,	0,	0,	0,	0,	0,	0,
			0,	0,	0,	0,	0,	0,	0,	0,	0,	0,	60,	127,	127,	109,	20,	0,	0,	0,	0,	0,	0,	0,	0,	0,	0,	0,	0,	0,
			0,	0,	0,	0,	0,	0,	0,	0,	0,	0,	60,	127,	103,	9,	0,	0,	0,	0,	0,	0,	0,	0,	0,	0,	0,	0,	0,	0,
			0,	0,	0,	0,	0,	0,	0,	0,	0,	0,	0,	0,	0,	0,	0,	0,	0,	0,	0,	0,	0,	0,	0,	0,	0,	0,	0,	0,

			0,	0,	0,	0,	0,	0,	0,	0,	0,	0,	0,	0,	0,	0,	0,	0,	0,	0,	0,	0,	0,	0,	0,	0,	0,	0,	0,	0,
			0,	0,	0,	0,	0,	0,	0,	0,	0,	0,	0,	0,	0,	0,	0,	0,	0,	0,	0,	0,	0,	0,	0,	0,	0,	0,	0,	0,
			0,	0,	0,	0,	0,	0,	0,	0,	0,	0,	0,	0,	0,	0,	0,	0,	0,	0,	0,	0,	0,	0,	0,	0,	0,	0,	0,	0,
			0,	0,	0,	0,	0,	0,	0,	0,	0,	0,	58,	62,	85,	127,	127,	75,	46,	0,	0,	0,	0,	0,	0,	0,	0,	0,	0,	0,
			0,	0,	0,	0,	0,	0,	0,	0,	0,	84,	126,	126,	126,	126,	126,	126,	109,	15,	0,	0,	0,	0,	0,	0,	0,	0,	0,	0,
			0,	0,	0,	0,	0,	0,	0,	0,	84,	126,	126,	126,	106,	71,	88,	126,	126,	61,	0,	0,	0,	0,	0,	0,	0,	0,	0,	0,
			0,	0,	0,	0,	0,	0,	0,	26,	125,	126,	105,	16,	6,	0,	3,	103,	126,	70,	0,	0,	0,	0,	0,	0,	0,	0,	0,	0,
			0,	0,	0,	0,	0,	0,	0,	38,	125,	105,	12,	0,	0,	0,	61,	124,	126,	32,	0,	0,	0,	0,	0,	0,	0,	0,	0,	0,
			0,	0,	0,	0,	0,	0,	0,	0,	15,	9,	0,	0,	0,	0,	104,	126,	126,	32,	0,	0,	0,	0,	0,	0,	0,	0,	0,	0,
			0,	0,	0,	0,	0,	0,	0,	0,	0,	0,	0,	0,	0,	58,	123,	126,	99,	5,	0,	0,	0,	0,	0,	0,	0,	0,	0,	0,
			0,	0,	0,	0,	0,	0,	0,	0,	0,	0,	0,	0,	38,	123,	126,	115,	31,	0,	0,	0,	0,	0,	0,	0,	0,	0,	0,	0,
			0,	0,	0,	0,	0,	0,	0,	0,	0,	0,	0,	0,	64,	126,	126,	72,	0,	0,	0,	0,	0,	0,	0,	0,	0,	0,	0,	0,
			0,	0,	0,	0,	0,	0,	0,	0,	0,	0,	0,	88,	123,	126,	79,	6,	0,	0,	0,	0,	0,	0,	0,	0,	0,	0,	0,	0,
			0,	0,	0,	0,	0,	0,	0,	0,	0,	0,	12,	117,	126,	116,	17,	0,	0,	0,	0,	0,	0,	0,	0,	0,	0,	0,	0,	0,
			0,	0,	0,	0,	0,	0,	0,	0,	0,	0,	99,	126,	126,	70,	0,	0,	0,	0,	0,	0,	0,	0,	0,	0,	0,	0,	0,	0,
			0,	0,	0,	0,	0,	0,	0,	0,	0,	39,	124,	126,	94,	6,	0,	0,	0,	0,	0,	0,	0,	0,	0,	0,	0,	0,	0,	0,
			0,	0,	0,	0,	0,	0,	0,	0,	9,	100,	126,	126,	70,	0,	0,	0,	0,	0,	0,	0,	0,	0,	0,	0,	0,	0,	0,	0,
			0,	0,	0,	0,	0,	0,	0,	0,	67,	126,	126,	86,	6,	0,	0,	0,	0,	0,	0,	0,	0,	0,	0,	0,	0,	0,	0,	0,
			0,	0,	0,	0,	0,	0,	0,	0,	124,	126,	126,	12,	0,	0,	0,	0,	0,	0,	0,	0,	0,	0,	0,	0,	0,	0,	0,	0,
			0,	0,	0,	0,	0,	0,	0,	0,	124,	126,	126,	21,	10,	10,	10,	10,	2,	0,	2,	10,	10,	18,	75,	75,	75,	73,	5,	0,
			0,	0,	0,	0,	0,	0,	0,	0,	124,	126,	126,	126,	126,	126,	126,	126,	84,	71,	83,	126,	126,	126,	126,	126,	126,	126,	61,	0,
			0,	0,	0,	0,	0,	0,	0,	0,	87,	126,	126,	126,	126,	126,	126,	126,	126,	126,	126,	126,	124,	123,	123,	84,	58,	58,	28,	0,
			0,	0,	0,	0,	0,	0,	0,	0,	0,	59,	61,	61,	61,	83,	126,	126,	126,	77,	61,	61,	20,	0,	0,	0,	0,	0,	0,	0,
			0,	0,	0,	0,	0,	0,	0,	0,	0,	0,	0,	0,	0,	0,	0,	0,	0,	0,	0,	0,	0,	0,	0,	0,	0,	0,	0,	0,
			0,	0,	0,	0,	0,	0,	0,	0,	0,	0,	0,	0,	0,	0,	0,	0,	0,	0,	0,	0,	0,	0,	0,	0,	0,	0,	0,	0,
			0,	0,	0,	0,	0,	0,	0,	0,	0,	0,	0,	0,	0,	0,	0,	0,	0,	0,	0,	0,	0,	0,	0,	0,	0,	0,	0,	0,
			0,	0,	0,	0,	0,	0,	0,	0,	0,	0,	0,	0,	0,	0,	0,	0,	0,	0,	0,	0,	0,	0,	0,	0,	0,	0,	0,	0,
			0,	0,	0,	0,	0,	0,	0,	0,	0,	0,	0,	0,	0,	0,	0,	0,	0,	0,	0,	0,	0,	0,	0,	0,	0,	0,	0,	0,

			0,	0,	0,	0,	0,	0,	0,	0,	0,	0,	0,	0,	0,	0,	0,	0,	0,	0,	0,	0,	0,	0,	0,	0,	0,	0,	0,	0,
			0,	0,	0,	0,	0,	0,	0,	0,	0,	0,	0,	0,	0,	0,	0,	0,	0,	0,	0,	0,	0,	0,	0,	0,	0,	0,	0,	0,
			0,	0,	0,	0,	0,	0,	0,	0,	0,	0,	0,	0,	0,	0,	0,	0,	0,	0,	0,	0,	0,	0,	0,	0,	0,	0,	0,	0,
			0,	0,	0,	0,	0,	0,	0,	0,	0,	0,	0,	0,	0,	0,	0,	0,	0,	0,	0,	0,	0,	0,	0,	0,	0,	0,	0,	0,
			0,	0,	0,	0,	0,	0,	0,	0,	0,	0,	0,	0,	0,	0,	0,	0,	19,	127,	54,	0,	0,	0,	0,	0,	0,	0,	0,	0,
			0,	0,	0,	0,	0,	0,	0,	0,	0,	0,	0,	0,	0,	0,	0,	0,	43,	126,	41,	0,	0,	0,	0,	0,	0,	0,	0,	0,
			0,	0,	0,	0,	0,	0,	0,	0,	0,	0,	0,	0,	0,	0,	0,	0,	67,	120,	0,	0,	0,	0,	0,	0,	0,	0,	0,	0,
			0,	0,	0,	0,	0,	0,	0,	0,	0,	0,	0,	0,	0,	0,	0,	22,	122,	75,	0,	0,	0,	0,	0,	0,	0,	0,	0,	0,
			0,	0,	0,	0,	0,	0,	0,	0,	0,	0,	0,	0,	0,	0,	0,	42,	127,	31,	0,	0,	0,	0,	0,	0,	0,	0,	0,	0,
			0,	0,	0,	0,	0,	0,	0,	0,	0,	0,	0,	0,	0,	0,	0,	101,	111,	5,	0,	0,	0,	0,	0,	0,	0,	0,	0,	0,
			0,	0,	0,	0,	0,	0,	0,	0,	0,	0,	0,	0,	0,	0,	16,	127,	108,	0,	0,	0,	0,	0,	0,	0,	0,	0,	0,	0,
			0,	0,	0,	0,	0,	0,	0,	0,	0,	0,	0,	0,	0,	0,	47,	127,	97,	0,	0,	0,	0,	0,	0,	0,	0,	0,	0,	0,
			0,	0,	0,	0,	0,	0,	0,	0,	0,	0,	0,	0,	0,	0,	70,	127,	38,	0,	0,	0,	0,	0,	0,	0,	0,	0,	0,	0,
			0,	0,	0,	0,	0,	0,	0,	0,	0,	0,	0,	0,	0,	28,	118,	102,	4,	0,	0,	0,	0,	0,	0,	0,	0,	0,	0,	0,
			0,	0,	0,	0,	0,	0,	0,	0,	0,	0,	0,	0,	0,	62,	127,	82,	0,	0,	0,	0,	0,	0,	0,	0,	0,	0,	0,	0,
			0,	0,	0,	0,	0,	0,	0,	0,	0,	0,	0,	0,	0,	85,	127,	40,	0,	0,	0,	0,	0,	0,	0,	0,	0,	0,	0,	0,
			0,	0,	0,	0,	0,	0,	0,	0,	0,	0,	0,	0,	12,	116,	107,	0,	0,	0,	0,	0,	0,	0,	0,	0,	0,	0,	0,	0,
			0,	0,	0,	0,	0,	0,	0,	0,	0,	0,	0,	0,	60,	127,	79,	0,	0,	0,	0,	0,	0,	0,	0,	0,	0,	0,	0,	0,
			0,	0,	0,	0,	0,	0,	0,	0,	0,	0,	0,	0,	75,	127,	71,	0,	0,	0,	0,	0,	0,	0,	0,	0,	0,	0,	0,	0,
			0,	0,	0,	0,	0,	0,	0,	0,	0,	0,	0,	0,	114,	127,	33,	0,	0,	0,	0,	0,	0,	0,	0,	0,	0,	0,	0,	0,
			0,	0,	0,	0,	0,	0,	0,	0,	0,	0,	0,	30,	125,	127,	33,	0,	0,	0,	0,	0,	0,	0,	0,	0,	0,	0,	0,	0,
			0,	0,	0,	0,	0,	0,	0,	0,	0,	0,	0,	70,	127,	102,	1,	0,	0,	0,	0,	0,	0,	0,	0,	0,	0,	0,	0,	0,
			0,	0,	0,	0,	0,	0,	0,	0,	0,	0,	5,	107,	127,	60,	0,	0,	0,	0,	0,	0,	0,	0,	0,	0,	0,	0,	0,	0,
			0,	0,	0,	0,	0,	0,	0,	0,	0,	0,	2,	99,	88,	5,	0,	0,	0,	0,	0,	0,	0,	0,	0,	0,	0,	0,	0,	0,
			0,	0,	0,	0,	0,	0,	0,	0,	0,	0,	0,	0,	0,	0,	0,	0,	0,	0,	0,	0,	0,	0,	0,	0,	0,	0,	0,	0,
			0,	0,	0,	0,	0,	0,	0,	0,	0,	0,	0,	0,	0,	0,	0,	0,	0,	0,	0,	0,	0,	0,	0,	0,	0,	0,	0,	0,
			0,	0,	0,	0,	0,	0,	0,	0,	0,	0,	0,	0,	0,	0,	0,	0,	0,	0,	0,	0,	0,	0,	0,	0,	0,	0,	0,	0,
			0,	0,	0,	0,	0,	0,	0,	0,	0,	0,	0,	0,	0,	0,	0,	0,	0,	0,	0,	0,	0,	0,	0,	0,	0,	0,	0,	0,

			0,	0,	0,	0,	0,	0,	0,	0,	0,	0,	0,	0,	0,	0,	0,	0,	0,	0,	0,	0,	0,	0,	0,	0,	0,	0,	0,	0,
			0,	0,	0,	0,	0,	0,	0,	0,	0,	0,	0,	0,	0,	0,	0,	0,	0,	0,	0,	0,	0,	0,	0,	0,	0,	0,	0,	0,
			0,	0,	0,	0,	0,	0,	0,	0,	0,	0,	0,	0,	0,	0,	0,	0,	0,	0,	0,	0,	0,	0,	0,	0,	0,	0,	0,	0,
			0,	0,	0,	0,	0,	0,	0,	0,	0,	0,	0,	0,	0,	0,	0,	0,	0,	0,	0,	0,	0,	0,	0,	0,	0,	0,	0,	0,
			0,	0,	0,	0,	0,	0,	0,	0,	0,	0,	0,	0,	5,	75,	126,	101,	15,	0,	0,	0,	0,	0,	0,	0,	0,	0,	0,	0,
			0,	0,	0,	0,	0,	0,	0,	0,	0,	0,	0,	0,	18,	125,	125,	126,	53,	0,	0,	0,	0,	0,	0,	0,	0,	0,	0,	0,
			0,	0,	0,	0,	0,	0,	0,	0,	0,	0,	0,	10,	98,	125,	125,	126,	53,	0,	0,	0,	0,	0,	0,	0,	0,	0,	0,	0,
			0,	0,	0,	0,	0,	0,	0,	0,	0,	0,	55,	95,	125,	125,	125,	126,	84,	54,	31,	0,	0,	0,	0,	0,	0,	0,	0,	0,
			0,	0,	0,	0,	0,	0,	0,	0,	0,	0,	126,	125,	125,	125,	125,	126,	125,	125,	110,	25,	0,	0,	0,	0,	0,	0,	0,	0,
			0,	0,	0,	0,	0,	0,	0,	0,	0,	91,	127,	126,	126,	126,	126,	117,	111,	126,	126,	126,	0,	0,	0,	0,	0,	0,	0,	0,
			0,	0,	0,	0,	0,	0,	0,	0,	31,	110,	126,	125,	125,	125,	73,	38,	31,	64,	125,	125,	52,	0,	0,	0,	0,	0,	0,	0,
			0,	0,	0,	0,	0,	0,	0,	16,	115,	125,	126,	125,	110,	68,	5,	0,	0,	15,	115,	125,	121,	56,	2,	0,	0,	0,	0,	0,
			0,	0,	0,	0,	0,	0,	0,	18,	125,	125,	126,	94,	10,	0,	0,	0,	0,	0,	54,	125,	126,	125,	17,	0,	0,	0,	0,	0,
			0,	0,	0,	0,	0,	0,	0,	18,	125,	125,	100,	15,	0,	0,	0,	0,	0,	0,	15,	100,	126,	125,	17,	0,	0,	0,	0,	0,
			0,	0,	0,	0,	0,	0,	0,	18,	126,	126,	0,	0,	0,	0,	0,	0,	0,	0,	16,	101,	127,	126,	82,	0,	0,	0,	0,	0,
			0,	0,	0,	0,	0,	0,	0,	70,	125,	125,	0,	0,	0,	0,	0,	0,	0,	0,	54,	125,	126,	125,	17,	0,	0,	0,	0,	0,
			0,	0,	0,	0,	0,	0,	0,	108,	125,	125,	0,	0,	0,	0,	0,	0,	10,	31,	115,	125,	126,	115,	15,	0,	0,	0,	0,	0,
			0,	0,	0,	0,	0,	0,	0,	108,	125,	125,	0,	0,	0,	0,	0,	0,	72,	125,	125,	125,	110,	30,	0,	0,	0,	0,	0,	0,
			0,	0,	0,	0,	0,	0,	0,	108,	125,	125,	0,	0,	0,	0,	0,	91,	110,	125,	125,	125,	90,	0,	0,	0,	0,	0,	0,	0,
			0,	0,	0,	0,	0,	0,	0,	109,	126,	126,	36,	36,	114,	126,	126,	127,	126,	126,	126,	126,	0,	0,	0,	0,	0,	0,	0,	0,
			0,	0,	0,	0,	0,	0,	0,	56,	125,	125,	126,	125,	125,	125,	125,	126,	125,	125,	125,	73,	0,	0,	0,	0,	0,	0,	0,	0,
			0,	0,	0,	0,	0,	0,	0,	15,	115,	125,	126,	125,	125,	125,	125,	126,	115,	94,	17,	5,	0,	0,	0,	0,	0,	0,	0,	0,
			0,	0,	0,	0,	0,	0,	0,	0,	31,	71,	126,	125,	125,	125,	125,	126,	53,	0,	0,	0,	0,	0,	0,	0,	0,	0,	0,	0,
			0,	0,	0,	0,	0,	0,	0,	0,	0,	0,	36,	87,	125,	86,	35,	36,	15,	0,	0,	0,	0,	0,	0,	0,	0,	0,	0,	0,
			0,	0,	0,	0,	0,	0,	0,	0,	0,	0,	0,	0,	0,	0,	0,	0,	0,	0,	0,	0,	0,	0,	0,	0,	0,	0,	0,	0,
			0,	0,	0,	0,	0,	0,	0,	0,	0,	0,	0,	0,	0,	0,	0,	0,	0,	0,	0,	0,	0,	0,	0,	0,	0,	0,	0,	0,
			0,	0,	0,	0,	0,	0,	0,	0,	0,	0,	0,	0,	0,	0,	0,	0,	0,	0,	0,	0,	0,	0,	0,	0,	0,	0,	0,	0,
			0,	0,	0,	0,	0,	0,	0,	0,	0,	0,	0,	0,	0,	0,	0,	0,	0,	0,	0,	0,	0,	0,	0,	0,	0,	0,	0,	0,

			0,	0,	0,	0,	0,	0,	0,	0,	0,	0,	0,	0,	0,	0,	0,	0,	0,	0,	0,	0,	0,	0,	0,	0,	0,	0,	0,	0,
			0,	0,	0,	0,	0,	0,	0,	0,	0,	0,	0,	0,	0,	0,	0,	0,	0,	0,	0,	0,	0,	0,	0,	0,	0,	0,	0,	0,
			0,	0,	0,	0,	0,	0,	0,	0,	0,	0,	0,	0,	0,	0,	0,	0,	0,	0,	0,	0,	0,	0,	0,	0,	0,	0,	0,	0,
			0,	0,	0,	0,	0,	0,	0,	0,	0,	0,	0,	0,	0,	0,	0,	0,	0,	0,	0,	0,	0,	0,	0,	0,	0,	0,	0,	0,
			0,	0,	0,	0,	0,	0,	0,	0,	0,	0,	0,	0,	0,	0,	0,	0,	0,	0,	0,	0,	0,	0,	0,	0,	0,	0,	0,	0,
			0,	0,	0,	0,	0,	0,	0,	0,	0,	0,	25,	112,	0,	0,	0,	0,	0,	0,	0,	35,	14,	0,	0,	0,	0,	0,	0,	0,
			0,	0,	0,	0,	0,	0,	0,	0,	0,	0,	60,	115,	0,	0,	0,	0,	0,	0,	0,	74,	84,	0,	0,	0,	0,	0,	0,	0,
			0,	0,	0,	0,	0,	0,	0,	0,	0,	2,	97,	115,	0,	0,	0,	0,	0,	0,	0,	48,	105,	5,	0,	0,	0,	0,	0,	0,
			0,	0,	0,	0,	0,	0,	0,	0,	0,	34,	126,	67,	0,	0,	0,	0,	0,	0,	0,	57,	126,	10,	0,	0,	0,	0,	0,	0,
			0,	0,	0,	0,	0,	0,	0,	0,	22,	118,	108,	6,	0,	0,	0,	0,	0,	0,	0,	96,	126,	10,	0,	0,	0,	0,	0,	0,
			0,	0,	0,	0,	0,	0,	0,	0,	84,	123,	26,	0,	0,	0,	0,	0,	0,	0,	9,	127,	126,	10,	0,	0,	0,	0,	0,	0,
			0,	0,	0,	0,	0,	0,	0,	42,	121,	105,	0,	0,	0,	0,	0,	0,	0,	0,	70,	126,	94,	2,	0,	0,	0,	0,	0,	0,
			0,	0,	0,	0,	0,	0,	0,	84,	126,	53,	0,	0,	0,	0,	0,	0,	0,	16,	116,	125,	33,	0,	0,	0,	0,	0,	0,	0,
			0,	0,	0,	0,	0,	0,	7,	112,	126,	0,	0,	0,	0,	0,	0,	0,	0,	67,	126,	105,	0,	0,	0,	0,	0,	0,	0,	0,
			0,	0,	0,	0,	0,	0,	11,	126,	82,	0,	0,	0,	0,	0,	0,	0,	0,	84,	126,	83,	0,	0,	0,	0,	0,	0,	0,	0,
			0,	0,	0,	0,	0,	0,	4,	102,	104,	9,	0,	0,	0,	0,	0,	0,	11,	126,	126,	53,	0,	0,	0,	0,	0,	0,	0,	0,
			0,	0,	0,	0,	0,	0,	0,	84,	126,	99,	42,	42,	42,	42,	64,	82,	97,	126,	126,	53,	0,	0,	0,	0,	0,	0,	0,	0,
			0,	0,	0,	0,	0,	0,	0,	20,	85,	122,	126,	126,	126,	126,	116,	115,	125,	126,	126,	4,	0,	0,	0,	0,	0,	0,	0,	0,
			0,	0,	0,	0,	0,	0,	0,	0,	0,	24,	42,	42,	42,	42,	0,	0,	80,	126,	126,	0,	0,	0,	0,	0,	0,	0,	0,	0,
			0,	0,	0,	0,	0,	0,	0,	0,	0,	0,	0,	0,	0,	0,	0,	0,	63,	126,	126,	22,	0,	0,	0,	0,	0,	0,	0,	0,
			0,	0,	0,	0,	0,	0,	0,	0,	0,	0,	0,	0,	0,	0,	0,	0,	64,	126,	126,	0,	0,	0,	0,	0,	0,	0,	0,	0,
			0,	0,	0,	0,	0,	0,	0,	0,	0,	0,	0,	0,	0,	0,	0,	0,	63,	126,	126,	0,	0,	0,	0,	0,	0,	0,	0,	0,
			0,	0,	0,	0,	0,	0,	0,	0,	0,	0,	0,	0,	0,	0,	0,	0,	67,	126,	122,	0,	0,	0,	0,	0,	0,	0,	0,	0,
			0,	0,	0,	0,	0,	0,	0,	0,	0,	0,	0,	0,	0,	0,	0,	0,	116,	118,	55,	0,	0,	0,	0,	0,	0,	0,	0,	0,
			0,	0,	0,	0,	0,	0,	0,	0,	0,	0,	0,	0,	0,	0,	0,	0,	89,	33,	0,	0,	0,	0,	0,	0,	0,	0,	0,	0,
			0,	0,	0,	0,	0,	0,	0,	0,	0,	0,	0,	0,	0,	0,	0,	0,	0,	0,	0,	0,	0,	0,	0,	0,	0,	0,	0,	0,
			0,	0,	0,	0,	0,	0,	0,	0,	0,	0,	0,	0,	0,	0,	0,	0,	0,	0,	0,	0,	0,	0,	0,	0,	0,	0,	0,	0,
			0,	0,	0,	0,	0,	0,	0,	0,	0,	0,	0,	0,	0,	0,	0,	0,	0,	0,	0,	0,	0,	0,	0,	0,	0,	0,	0,	0,

			0,	0,	0,	0,	0,	0,	0,	0,	0,	0,	0,	0,	0,	0,	0,	0,	0,	0,	0,	0,	0,	0,	0,	0,	0,	0,	0,	0,
			0,	0,	0,	0,	0,	0,	0,	0,	0,	0,	0,	0,	0,	0,	0,	0,	0,	0,	0,	0,	0,	0,	0,	0,	0,	0,	0,	0,
			0,	0,	0,	0,	0,	0,	0,	0,	0,	0,	0,	0,	0,	0,	0,	0,	0,	0,	0,	0,	0,	0,	0,	0,	0,	0,	0,	0,
			0,	0,	0,	0,	0,	0,	0,	0,	0,	0,	0,	0,	0,	0,	0,	0,	0,	0,	0,	0,	0,	0,	0,	0,	0,	0,	0,	0,
			0,	0,	0,	0,	0,	0,	0,	0,	0,	0,	0,	0,	0,	0,	0,	0,	0,	0,	0,	0,	0,	0,	0,	0,	0,	0,	0,	0,
			0,	0,	0,	0,	0,	0,	0,	0,	0,	0,	0,	0,	0,	0,	0,	0,	38,	127,	53,	1,	0,	0,	0,	0,	0,	0,	0,	0,
			0,	0,	0,	0,	0,	0,	0,	0,	0,	0,	0,	0,	0,	0,	0,	9,	113,	127,	127,	4,	0,	0,	0,	0,	0,	0,	0,	0,
			0,	0,	0,	0,	0,	0,	0,	0,	0,	0,	0,	0,	0,	0,	0,	40,	127,	127,	82,	0,	0,	0,	0,	0,	0,	0,	0,	0,
			0,	0,	0,	0,	0,	0,	0,	0,	0,	0,	0,	0,	0,	0,	3,	101,	127,	127,	36,	0,	0,	0,	0,	0,	0,	0,	0,	0,
			0,	0,	0,	0,	0,	0,	0,	0,	0,	0,	0,	0,	0,	0,	26,	127,	127,	125,	0,	0,	0,	0,	0,	0,	0,	0,	0,	0,
			0,	0,	0,	0,	0,	0,	0,	0,	0,	0,	0,	0,	0,	0,	67,	127,	127,	90,	0,	0,	0,	0,	0,	0,	0,	0,	0,	0,
			0,	0,	0,	0,	0,	0,	0,	0,	0,	0,	0,	0,	0,	0,	98,	127,	124,	24,	0,	0,	0,	0,	0,	0,	0,	0,	0,	0,
			0,	0,	0,	0,	0,	0,	0,	0,	0,	0,	0,	0,	0,	29,	127,	127,	118,	0,	0,	0,	0,	0,	0,	0,	0,	0,	0,	0,
			0,	0,	0,	0,	0,	0,	0,	0,	0,	0,	0,	0,	0,	55,	127,	127,	66,	0,	0,	0,	0,	0,	0,	0,	0,	0,	0,	0,
			0,	0,	0,	0,	0,	0,	0,	0,	0,	0,	0,	0,	0,	81,	127,	119,	14,	0,	0,	0,	0,	0,	0,	0,	0,	0,	0,	0,
			0,	0,	0,	0,	0,	0,	0,	0,	0,	0,	0,	0,	30,	126,	127,	111,	0,	0,	0,	0,	0,	0,	0,	0,	0,	0,	0,	0,
			0,	0,	0,	0,	0,	0,	0,	0,	0,	0,	0,	0,	39,	127,	127,	77,	0,	0,	0,	0,	0,	0,	0,	0,	0,	0,	0,	0,
			0,	0,	0,	0,	0,	0,	0,	0,	0,	0,	0,	0,	81,	127,	119,	26,	0,	0,	0,	0,	0,	0,	0,	0,	0,	0,	0,	0,
			0,	0,	0,	0,	0,	0,	0,	0,	0,	0,	0,	14,	126,	127,	105,	0,	0,	0,	0,	0,	0,	0,	0,	0,	0,	0,	0,	0,
			0,	0,	0,	0,	0,	0,	0,	0,	0,	0,	0,	43,	127,	127,	65,	0,	0,	0,	0,	0,	0,	0,	0,	0,	0,	0,	0,	0,
			0,	0,	0,	0,	0,	0,	0,	0,	0,	0,	0,	52,	127,	117,	10,	0,	0,	0,	0,	0,	0,	0,	0,	0,	0,	0,	0,	0,
			0,	0,	0,	0,	0,	0,	0,	0,	0,	0,	0,	87,	127,	102,	2,	0,	0,	0,	0,	0,	0,	0,	0,	0,	0,	0,	0,	0,
			0,	0,	0,	0,	0,	0,	0,	0,	0,	0,	2,	105,	127,	98,	0,	0,	0,	0,	0,	0,	0,	0,	0,	0,	0,	0,	0,	0,
			0,	0,	0,	0,	0,	0,	0,	0,	0,	0,	1,	79,	127,	80,	0,	0,	0,	0,	0,	0,	0,	0,	0,	0,	0,	0,	0,	0,
			0,	0,	0,	0,	0,	0,	0,	0,	0,	0,	0,	13,	78,	53,	0,	0,	0,	0,	0,	0,	0,	0,	0,	0,	0,	0,	0,	0,
			0,	0,	0,	0,	0,	0,	0,	0,	0,	0,	0,	0,	0,	0,	0,	0,	0,	0,	0,	0,	0,	0,	0,	0,	0,	0,	0,	0,
			0,	0,	0,	0,	0,	0,	0,	0,	0,	0,	0,	0,	0,	0,	0,	0,	0,	0,	0,	0,	0,	0,	0,	0,	0,	0,	0,	0,
			0,	0,	0,	0,	0,	0,	0,	0,	0,	0,	0,	0,	0,	0,	0,	0,	0,	0,	0,	0,	0,	0,	0,	0,	0,	0,	0,	0,

			0,	0,	0,	0,	0,	0,	0,	0,	0,	0,	0,	0,	0,	0,	0,	0,	0,	0,	0,	0,	0,	0,	0,	0,	0,	0,	0,	0,
			0,	0,	0,	0,	0,	0,	0,	0,	0,	0,	0,	0,	0,	0,	0,	0,	0,	0,	0,	0,	0,	0,	0,	0,	0,	0,	0,	0,
			0,	0,	0,	0,	0,	0,	0,	0,	0,	0,	0,	0,	0,	0,	0,	0,	0,	0,	0,	0,	0,	0,	0,	0,	0,	0,	0,	0,
			0,	0,	0,	0,	0,	0,	0,	0,	0,	0,	0,	0,	0,	0,	0,	0,	0,	0,	0,	0,	0,	0,	0,	0,	0,	0,	0,	0,
			0,	0,	0,	0,	0,	0,	0,	0,	0,	0,	0,	0,	0,	0,	0,	0,	0,	0,	0,	0,	0,	0,	0,	0,	0,	0,	0,	0,
			0,	0,	0,	0,	0,	0,	0,	0,	0,	11,	96,	67,	16,	0,	0,	0,	0,	0,	0,	0,	0,	7,	38,	2,	0,	0,	0,	0,
			0,	0,	0,	0,	0,	0,	0,	0,	8,	117,	125,	84,	0,	0,	0,	0,	0,	0,	0,	0,	7,	110,	120,	18,	0,	0,	0,	0,
			0,	0,	0,	0,	0,	0,	0,	10,	94,	126,	73,	0,	0,	0,	0,	0,	0,	0,	0,	0,	69,	126,	50,	0,	0,	0,	0,	0,
			0,	0,	0,	0,	0,	0,	0,	35,	126,	126,	10,	0,	0,	0,	0,	0,	0,	0,	0,	21,	127,	86,	6,	0,	0,	0,	0,	0,
			0,	0,	0,	0,	0,	0,	11,	76,	126,	48,	0,	0,	0,	0,	0,	0,	0,	0,	21,	115,	127,	46,	0,	0,	0,	0,	0,	0,
			0,	0,	0,	0,	0,	0,	81,	127,	102,	5,	0,	0,	0,	0,	0,	0,	0,	0,	52,	127,	79,	0,	0,	0,	0,	0,	0,	0,
			0,	0,	0,	0,	0,	0,	81,	126,	89,	2,	0,	0,	0,	0,	0,	0,	4,	65,	118,	126,	0,	0,	0,	0,	0,	0,	0,	0,
			0,	0,	0,	0,	0,	0,	81,	126,	126,	95,	87,	35,	35,	35,	35,	66,	98,	126,	126,	84,	0,	0,	0,	0,	0,	0,	0,	0,
			0,	0,	0,	0,	0,	0,	25,	114,	126,	126,	127,	126,	126,	126,	126,	127,	126,	126,	109,	17,	0,	0,	0,	0,	0,	0,	0,	0,
			0,	0,	0,	0,	0,	0,	0,	8,	32,	68,	127,	116,	68,	68,	68,	22,	126,	126,	80,	0,	0,	0,	0,	0,	0,	0,	0,	0,
			0,	0,	0,	0,	0,	0,	0,	0,	0,	0,	0,	0,	0,	0,	0,	17,	127,	103,	10,	0,	0,	0,	0,	0,	0,	0,	0,	0,
			0,	0,	0,	0,	0,	0,	0,	0,	0,	0,	0,	0,	0,	0,	0,	80,	126,	34,	0,	0,	0,	0,	0,	0,	0,	0,	0,	0,
			0,	0,	0,	0,	0,	0,	0,	0,	0,	0,	0,	0,	0,	0,	42,	127,	120,	25,	0,	0,	0,	0,	0,	0,	0,	0,	0,	0,
			0,	0,	0,	0,	0,	0,	0,	0,	0,	0,	0,	0,	0,	0,	79,	127,	82,	0,	0,	0,	0,	0,	0,	0,	0,	0,	0,	0,
			0,	0,	0,	0,	0,	0,	0,	0,	0,	0,	0,	0,	0,	0,	115,	122,	25,	0,	0,	0,	0,	0,	0,	0,	0,	0,	0,	0,
			0,	0,	0,	0,	0,	0,	0,	0,	0,	0,	0,	0,	0,	52,	127,	116,	0,	0,	0,	0,	0,	0,	0,	0,	0,	0,	0,	0,
			0,	0,	0,	0,	0,	0,	0,	0,	0,	0,	0,	0,	0,	104,	126,	78,	0,	6,	15,	0,	0,	0,	0,	0,	0,	0,	0,	0,
			0,	0,	0,	0,	0,	0,	0,	0,	0,	0,	0,	0,	0,	104,	126,	77,	45,	102,	80,	0,	0,	0,	0,	0,	0,	0,	0,	0,
			0,	0,	0,	0,	0,	0,	0,	0,	0,	0,	0,	0,	0,	104,	126,	127,	126,	77,	14,	0,	0,	0,	0,	0,	0,	0,	0,	0,
			0,	0,	0,	0,	0,	0,	0,	0,	0,	0,	0,	0,	0,	30,	95,	64,	11,	3,	0,	0,	0,	0,	0,	0,	0,	0,	0,	0,
			0,	0,	0,	0,	0,	0,	0,	0,	0,	0,	0,	0,	0,	0,	0,	0,	0,	0,	0,	0,	0,	0,	0,	0,	0,	0,	0,	0,
			0,	0,	0,	0,	0,	0,	0,	0,	0,	0,	0,	0,	0,	0,	0,	0,	0,	0,	0,	0,	0,	0,	0,	0,	0,	0,	0,	0,
			0,	0,	0,	0,	0,	0,	0,	0,	0,	0,	0,	0,	0,	0,	0,	0,	0,	0,	0,	0,	0,	0,	0,	0,	0,	0,	0,	0,

			0,	0,	0,	0,	0,	0,	0,	0,	0,	0,	0,	0,	0,	0,	0,	0,	0,	0,	0,	0,	0,	0,	0,	0,	0,	0,	0,	0,
			0,	0,	0,	0,	0,	0,	0,	0,	0,	0,	0,	0,	0,	0,	0,	0,	0,	0,	0,	0,	0,	0,	0,	0,	0,	0,	0,	0,
			0,	0,	0,	0,	0,	0,	0,	0,	0,	0,	0,	0,	0,	0,	0,	0,	0,	0,	0,	0,	0,	0,	0,	0,	0,	0,	0,	0,
			0,	0,	0,	0,	0,	0,	0,	0,	0,	0,	0,	0,	0,	0,	0,	0,	0,	0,	0,	0,	0,	0,	0,	0,	0,	0,	0,	0,
			0,	0,	0,	0,	0,	0,	0,	0,	0,	0,	0,	0,	0,	0,	0,	0,	0,	0,	0,	0,	0,	0,	0,	0,	0,	0,	0,	0,
			0,	0,	0,	0,	0,	0,	0,	0,	0,	0,	0,	0,	0,	0,	0,	0,	0,	0,	0,	0,	0,	0,	0,	0,	0,	0,	0,	0,
			0,	0,	0,	0,	0,	0,	0,	0,	0,	0,	0,	7,	74,	96,	2,	0,	0,	0,	0,	0,	0,	0,	0,	0,	0,	0,	0,	0,
			0,	0,	0,	0,	0,	0,	0,	0,	0,	0,	45,	112,	126,	126,	9,	0,	0,	0,	0,	0,	0,	0,	0,	0,	0,	0,	0,	0,
			0,	0,	0,	0,	0,	0,	0,	0,	0,	14,	117,	127,	126,	126,	83,	9,	0,	0,	0,	0,	0,	0,	0,	0,	0,	0,	0,	0,
			0,	0,	0,	0,	0,	0,	0,	0,	0,	72,	126,	127,	126,	126,	126,	119,	57,	3,	0,	0,	0,	0,	0,	0,	0,	0,	0,	0,
			0,	0,	0,	0,	0,	0,	0,	0,	15,	120,	126,	104,	92,	126,	126,	126,	115,	12,	0,	0,	0,	0,	0,	0,	0,	0,	0,	0,
			0,	0,	0,	0,	0,	0,	0,	0,	39,	127,	96,	0,	4,	49,	109,	127,	127,	100,	9,	0,	0,	0,	0,	0,	0,	0,	0,	0,
			0,	0,	0,	0,	0,	0,	0,	0,	43,	126,	40,	0,	0,	0,	91,	126,	127,	95,	6,	0,	0,	0,	0,	0,	0,	0,	0,	0,
			0,	0,	0,	0,	0,	0,	0,	0,	87,	126,	77,	0,	0,	0,	117,	126,	127,	67,	0,	0,	0,	0,	0,	0,	0,	0,	0,	0,
			0,	0,	0,	0,	0,	0,	0,	0,	43,	126,	104,	20,	42,	83,	125,	118,	127,	118,	21,	0,	0,	0,	0,	0,	0,	0,	0,	0,
			0,	0,	0,	0,	0,	0,	0,	0,	9,	119,	126,	127,	126,	126,	92,	18,	108,	126,	76,	0,	0,	0,	0,	0,	0,	0,	0,	0,
			0,	0,	0,	0,	0,	0,	0,	0,	0,	34,	120,	127,	127,	72,	4,	0,	67,	127,	111,	17,	0,	0,	0,	0,	0,	0,	0,	0,
			0,	0,	0,	0,	0,	0,	0,	0,	0,	0,	34,	79,	71,	6,	0,	0,	4,	87,	126,	80,	0,	0,	0,	0,	0,	0,	0,	0,
			0,	0,	0,	0,	0,	0,	0,	0,	0,	0,	0,	0,	0,	0,	0,	0,	0,	44,	126,	113,	9,	0,	0,	0,	0,	0,	0,	0,
			0,	0,	0,	0,	0,	0,	0,	0,	0,	0,	0,	0,	0,	0,	0,	0,	0,	1,	83,	126,	63,	0,	0,	0,	0,	0,	0,	0,
			0,	0,	0,	0,	0,	0,	0,	0,	0,	0,	0,	0,	0,	0,	0,	0,	0,	0,	24,	122,	126,	19,	0,	0,	0,	0,	0,	0,
			0,	0,	0,	0,	0,	0,	0,	0,	0,	0,	0,	0,	0,	0,	0,	0,	0,	0,	0,	57,	127,	86,	4,	0,	0,	0,	0,	0,
			0,	0,	0,	0,	0,	0,	0,	0,	0,	0,	0,	0,	0,	0,	0,	0,	0,	0,	0,	10,	109,	127,	23,	0,	0,	0,	0,	0,
			0,	0,	0,	0,	0,	0,	0,	0,	0,	0,	0,	0,	0,	0,	0,	0,	0,	0,	0,	0,	15,	127,	82,	0,	0,	0,	0,	0,
			0,	0,	0,	0,	0,	0,	0,	0,	0,	0,	0,	0,	0,	0,	0,	0,	0,	0,	0,	0,	0,	93,	122,	21,	0,	0,	0,	0,
			0,	0,	0,	0,	0,	0,	0,	0,	0,	0,	0,	0,	0,	0,	0,	0,	0,	0,	0,	0,	0,	7,	111,	39,	0,	0,	0,	0,
			0,	0,	0,	0,	0,	0,	0,	0,	0,	0,	0,	0,	0,	0,	0,	0,	0,	0,	0,	0,	0,	0,	0,	0,	0,	0,	0,	0,
			0,	0,	0,	0,	0,	0,	0,	0,	0,	0,	0,	0,	0,	0,	0,	0,	0,	0,	0,	0,	0,	0,	0,	0,	0,	0,	0,	0,

			0,	0,	0,	0,	0,	0,	0,	0,	0,	0,	0,	0,	0,	0,	0,	0,	0,	0,	0,	0,	0,	0,	0,	0,	0,	0,	0,	0,
			0,	0,	0,	0,	0,	0,	0,	0,	0,	0,	0,	0,	0,	0,	0,	0,	0,	0,	0,	0,	0,	0,	0,	0,	0,	0,	0,	0,
			0,	0,	0,	0,	0,	0,	0,	0,	0,	0,	0,	0,	0,	0,	0,	0,	0,	0,	0,	0,	0,	0,	0,	0,	0,	0,	0,	0,
			0,	0,	0,	0,	0,	0,	0,	0,	0,	0,	0,	0,	0,	0,	0,	0,	0,	0,	0,	0,	0,	0,	0,	0,	0,	0,	0,	0,
			0,	0,	0,	0,	0,	0,	0,	0,	0,	0,	0,	0,	0,	0,	0,	0,	0,	8,	23,	23,	23,	8,	64,	42,	23,	0,	0,	0,
			0,	0,	0,	0,	0,	0,	0,	0,	0,	0,	0,	0,	0,	0,	0,	37,	76,	108,	126,	126,	126,	107,	123,	126,	126,	0,	0,	0,
			0,	0,	0,	0,	0,	0,	0,	0,	0,	0,	0,	0,	17,	71,	122,	126,	126,	126,	126,	126,	126,	126,	126,	126,	126,	0,	0,	0,
			0,	0,	0,	0,	0,	0,	0,	0,	0,	0,	0,	0,	31,	126,	126,	126,	126,	126,	126,	126,	106,	85,	85,	85,	85,	0,	0,	0,
			0,	0,	0,	0,	0,	0,	0,	0,	10,	66,	36,	0,	28,	119,	113,	119,	84,	62,	34,	10,	5,	0,	0,	0,	0,	0,	0,	0,
			0,	0,	0,	0,	0,	0,	0,	5,	103,	126,	39,	0,	0,	16,	0,	15,	1,	0,	0,	0,	0,	0,	0,	0,	0,	0,	0,	0,
			0,	0,	0,	0,	0,	0,	3,	88,	126,	66,	5,	0,	0,	0,	0,	0,	0,	0,	0,	0,	0,	0,	0,	0,	0,	0,	0,	0,
			0,	0,	0,	0,	0,	6,	66,	126,	116,	7,	0,	0,	0,	0,	0,	0,	0,	0,	0,	0,	0,	0,	0,	0,	0,	0,	0,	0,
			0,	0,	0,	0,	0,	46,	126,	111,	14,	0,	0,	0,	0,	0,	0,	0,	0,	0,	0,	0,	0,	0,	0,	0,	0,	0,	0,	0,
			0,	0,	0,	0,	0,	75,	126,	87,	0,	0,	0,	0,	0,	0,	0,	0,	0,	0,	0,	0,	0,	0,	0,	0,	0,	0,	0,	0,
			0,	0,	0,	0,	0,	117,	126,	123,	63,	24,	0,	0,	0,	0,	0,	0,	0,	0,	0,	0,	0,	0,	0,	0,	0,	0,	0,	0,
			0,	0,	0,	0,	0,	127,	126,	126,	126,	125,	73,	45,	60,	42,	21,	21,	42,	14,	0,	0,	0,	0,	0,	0,	0,	0,	0,	0,
			0,	0,	0,	0,	0,	69,	126,	126,	126,	126,	126,	126,	126,	126,	126,	126,	126,	116,	84,	0,	0,	0,	0,	0,	0,	0,	0,	0,
			0,	0,	0,	0,	0,	1,	26,	109,	111,	125,	126,	126,	126,	126,	126,	126,	126,	126,	126,	62,	0,	0,	0,	0,	0,	0,	0,	0,
			0,	0,	0,	0,	0,	0,	0,	0,	0,	33,	36,	100,	126,	126,	126,	126,	126,	126,	126,	87,	0,	0,	0,	0,	0,	0,	0,	0,
			0,	0,	0,	0,	0,	0,	0,	0,	0,	0,	0,	60,	126,	124,	76,	25,	82,	126,	126,	87,	0,	0,	0,	0,	0,	0,	0,	0,
			0,	0,	0,	0,	0,	0,	0,	0,	0,	0,	0,	25,	126,	126,	126,	94,	126,	126,	126,	74,	0,	0,	0,	0,	0,	0,	0,	0,
			0,	0,	0,	0,	0,	0,	0,	0,	0,	0,	0,	4,	83,	126,	126,	126,	126,	125,	87,	5,	0,	0,	0,	0,	0,	0,	0,	0,
			0,	0,	0,	0,	0,	0,	0,	0,	0,	0,	0,	0,	11,	90,	115,	126,	110,	64,	0,	0,	0,	0,	0,	0,	0,	0,	0,	0,
			0,	0,	0,	0,	0,	0,	0,	0,	0,	0,	0,	0,	0,	0,	46,	74,	11,	0,	0,	0,	0,	0,	0,	0,	0,	0,	0,	0,
			0,	0,	0,	0,	0,	0,	0,	0,	0,	0,	0,	0,	0,	0,	0,	0,	0,	0,	0,	0,	0,	0,	0,	0,	0,	0,	0,	0,
			0,	0,	0,	0,	0,	0,	0,	0,	0,	0,	0,	0,	0,	0,	0,	0,	0,	0,	0,	0,	0,	0,	0,	0,	0,	0,	0,	0,
			0,	0,	0,	0,	0,	0,	0,	0,	0,	0,	0,	0,	0,	0,	0,	0,	0,	0,	0,	0,	0,	0,	0,	0,	0,	0,	0,	0,
			0,	0,	0,	0,	0,	0,	0,	0,	0,	0,	0,	0,	0,	0,	0,	0,	0,	0,	0,	0,	0,	0,	0,	0,	0,	0,	0,	0,

			0,	0,	0,	0,	0,	0,	0,	0,	0,	0,	0,	0,	0,	0,	0,	0,	0,	0,	0,	0,	0,	0,	0,	0,	0,	0,	0,	0,
			0,	0,	0,	0,	0,	0,	0,	0,	0,	0,	0,	0,	0,	0,	0,	0,	0,	0,	0,	0,	0,	0,	0,	0,	0,	0,	0,	0,
			0,	0,	0,	0,	0,	0,	0,	0,	0,	0,	0,	0,	0,	0,	0,	0,	0,	0,	0,	0,	0,	0,	0,	0,	0,	0,	0,	0,
			0,	0,	0,	0,	0,	0,	0,	0,	0,	0,	0,	0,	0,	0,	0,	0,	0,	0,	0,	0,	0,	0,	0,	0,	0,	0,	0,	0,
			0,	0,	0,	0,	0,	0,	0,	0,	0,	0,	0,	0,	0,	0,	0,	0,	0,	0,	0,	0,	0,	0,	0,	0,	0,	0,	0,	0,
			0,	0,	0,	0,	0,	0,	0,	0,	0,	0,	0,	0,	0,	0,	0,	0,	0,	0,	0,	0,	0,	0,	0,	0,	0,	0,	0,	0,
			0,	0,	0,	0,	0,	0,	0,	0,	0,	0,	0,	0,	0,	0,	0,	0,	0,	0,	0,	0,	0,	0,	0,	0,	0,	0,	0,	0,
			0,	0,	0,	0,	0,	0,	0,	0,	0,	0,	0,	0,	0,	18,	28,	68,	100,	99,	47,	18,	0,	0,	0,	0,	0,	0,	0,	0,
			0,	0,	0,	0,	0,	0,	0,	0,	0,	0,	0,	22,	76,	117,	127,	127,	127,	127,	127,	125,	105,	75,	3,	0,	0,	0,	0,	0,
			0,	0,	0,	0,	0,	0,	0,	0,	0,	23,	76,	120,	127,	127,	113,	83,	66,	125,	100,	127,	114,	112,	52,	0,	0,	0,	0,	0,
			0,	0,	0,	0,	0,	0,	0,	0,	76,	117,	127,	127,	93,	71,	4,	0,	0,	95,	20,	99,	123,	111,	126,	10,	0,	0,	0,	0,
			0,	0,	0,	0,	0,	0,	4,	63,	126,	127,	116,	64,	5,	0,	0,	0,	0,	105,	21,	35,	127,	127,	127,	10,	0,	0,	0,	0,
			0,	0,	0,	0,	0,	0,	36,	121,	127,	114,	27,	0,	0,	0,	0,	1,	16,	58,	112,	121,	127,	127,	81,	2,	0,	0,	0,	0,
			0,	0,	0,	0,	0,	0,	37,	120,	127,	111,	54,	69,	89,	89,	84,	105,	125,	115,	127,	127,	127,	116,	19,	0,	0,	0,	0,	0,
			0,	0,	0,	0,	0,	0,	4,	87,	12,	126,	127,	127,	127,	125,	127,	127,	127,	127,	127,	126,	85,	12,	0,	0,	0,	0,	0,	0,
			0,	0,	0,	0,	0,	0,	0,	0,	8,	68,	97,	88,	73,	76,	100,	127,	127,	127,	127,	75,	8,	0,	0,	0,	0,	0,	0,	0,
			0,	0,	0,	0,	0,	0,	0,	0,	0,	0,	0,	0,	0,	0,	81,	127,	127,	120,	49,	1,	0,	0,	0,	0,	0,	0,	0,	0,
			0,	0,	0,	0,	0,	0,	0,	0,	0,	0,	0,	0,	0,	59,	125,	127,	127,	45,	0,	0,	0,	0,	0,	0,	0,	0,	0,	0,
			0,	0,	0,	0,	0,	0,	0,	0,	0,	0,	0,	0,	50,	121,	127,	127,	105,	3,	0,	0,	0,	0,	0,	0,	0,	0,	0,	0,
			0,	0,	0,	0,	0,	0,	0,	0,	0,	0,	0,	27,	120,	127,	127,	121,	29,	0,	0,	0,	0,	0,	0,	0,	0,	0,	0,	0,
			0,	0,	0,	0,	0,	0,	0,	0,	0,	0,	0,	65,	127,	127,	122,	32,	0,	0,	0,	0,	0,	0,	0,	0,	0,	0,	0,	0,
			0,	0,	0,	0,	0,	0,	0,	0,	0,	0,	6,	124,	127,	127,	76,	0,	0,	0,	0,	0,	0,	0,	0,	0,	0,	0,	0,	0,
			0,	0,	0,	0,	0,	0,	0,	0,	0,	6,	114,	127,	127,	104,	4,	0,	0,	0,	0,	0,	0,	0,	0,	0,	0,	0,	0,	0,
			0,	0,	0,	0,	0,	0,	0,	0,	0,	39,	127,	127,	127,	33,	0,	0,	0,	0,	0,	0,	0,	0,	0,	0,	0,	0,	0,	0,
			0,	0,	0,	0,	0,	0,	0,	0,	0,	104,	127,	127,	68,	0,	0,	0,	0,	0,	0,	0,	0,	0,	0,	0,	0,	0,	0,	0,
			0,	0,	0,	0,	0,	0,	0,	0,	0,	113,	127,	116,	12,	0,	0,	0,	0,	0,	0,	0,	0,	0,	0,	0,	0,	0,	0,	0,
			0,	0,	0,	0,	0,	0,	0,	0,	0,	56,	127,	54,	0,	0,	0,	0,	0,	0,	0,	0,	0,	0,	0,	0,	0,	0,	0,	0,
			0,	0,	0,	0,	0,	0,	0,	0,	0,	0,	0,	0,	0,	0,	0,	0,	0,	0,	0,	0,	0,	0,	0,	0,	0,	0,	0,	0
	};

	//FRESULT res; /* FatFs function common result code */
	//uint32_t byteswritten, bytesread; /* File write/read counts */
	//uint8_t wtext[] = "STM32 FATFS works great!"; /* File write buffer */
	//uint8_t rtext[_MAX_SS];/* File read buffer */
  /* USER CODE END 1 */

  /* MCU Configuration--------------------------------------------------------*/

  /* Reset of all peripherals, Initializes the Flash interface and the Systick. */
  HAL_Init();

  /* Configure the system clock */
  SystemClock_Config();

/* Configure the peripherals common clocks */
  PeriphCommonClock_Config();

  /* USER CODE BEGIN SysInit */
 // HAL_SYSTICK_Config(HAL_RCC_GetHCLKFreq()/1000);
 // HAL_SYSTICK_CLKSourceConfig(SYSTICK_CLKSOURCE_HCLK);
 // HAL_NVIC_SetPriority(SysTick_IRQn,0,0);
  //HAL_TIM_Base_Start_IT(&htim5);

  //HAL_TIM_Base_Start_IT(&htim5);
  /* USER CODE END SysInit */

  /* Initialize all configured peripherals */
  MX_GPIO_Init();
  MX_DMA_Init();
  MX_ADC1_Init();
  MX_ADC3_Init();
  MX_DCMI_Init();
  MX_DFSDM1_Init();
  MX_FMC_Init();
  MX_USART1_UART_Init();
  MX_SAI1_Init();
  MX_SDMMC1_SD_Init();
  MX_SPI2_Init();
  MX_USB_DEVICE_Init();
  MX_TIM6_Init();
  MX_FATFS_Init();
  MX_TIM5_Init();
  /* USER CODE BEGIN 2 */

  //HAL_TIM_Base_Start_IT(&htim6);
  uint64_t timer_start;
  uint64_t timer_end,timer_end2;
  uint64_t SysTickCnt_start;
  uint64_t SysTickCnt_end;
  uint64_t SysTickCnt_ms;
  uint64_t us_SysTickCnt_start;
  uint64_t us_SysTickCnt_end;
  uint64_t SysTickCnt_us;

  HAL_TIM_Base_Start(&htim6);
  /* USER CODE END 2 */

  /* Infinite loop */
  /* USER CODE BEGIN WHILE */
  while (1)
//  {

	  //int TxBufferlen1=0;
	  //int TxBufferlen2=0;
	  //uint8_t buf1[200];
	  //uint8_t buf2[200];
  //}
    /* USER CODE END WHILE */

    /* USER CODE BEGIN 3 */
	  // timer test
  {
	  char uart_buf[50];
	  int uart_buf_len;
	  uint16_t timer_val,timer_val1;

	  timer_val = __HAL_TIM_GET_COUNTER(&htim6);

	  // 50ms
	  HAL_GPIO_WritePin(GPIOB, GPIO_PIN_13, GPIO_PIN_SET);
	  HAL_Delay(50);
	  HAL_GPIO_WritePin(GPIOB, GPIO_PIN_13, GPIO_PIN_RESET);

	  // SAVE TIME
	  timer_val1 = __HAL_TIM_GET_COUNTER(&htim6) - timer_val;

	  // SHOW TIME
	  uart_buf_len = sprintf(uart_buf, "%u us\r\n", timer_val1);
	  HAL_UART_Transmit(&huart1, (uint8_t *)uart_buf, uart_buf_len, 100);

	 // HAL_Delay(1000);
	  }

	 // SysTickCnt_start = TimerCount;
	  //SysTickCnt_end = SysTickCnt2;
	 // us_SysTickCnt_start = us_SysTickCnt;
	  /*
	  htim6.Instance->CNT;
	  HAL_GPIO_WritePin(GPIOB, GPIO_PIN_13, GPIO_PIN_SET);
	  HAL_Delay(1000);
	  HAL_GPIO_WritePin(GPIOB, GPIO_PIN_13, GPIO_PIN_RESET);
	  HAL_Delay(1000);
	  SysTickCnt_end = SysTickCnt2;
	  SysTickCnt_ms= SysTickCnt_end - SysTickCnt_start;
	  //us_SysTickCnt_end = us_SysTickCnt1;

	  TxBufferlen1 = sprintf(buf1,"%ld\n",SysTickCnt_start);
	  TxBufferlen2 = sprintf(buf2,"%ld\n",SysTickCnt_ms);//, us_SysTickCnt_end, SysTickCnt_us);
	  HAL_UART_Transmit(&huart1, buf1, TxBufferlen1, 1000);
	  HAL_Delay(10);
	  HAL_UART_Transmit(&huart1, buf2, TxBufferlen2, 1000);
	  */

/*
  	 for(int i=0; i<5; i++)
  	 {
	  	HAL_Delay(2000);
	  	nnom_model_t* model;
	  	nnom_predict_t * pre;
	  	//int8_t* input;
	  	float prob;
	  	uint32_t label;
	  	uint64_t size = 7968; 	////912 // 1696	// 7968
	  	uint8_t buf[100];
	  	uint8_t buf1[100];
	  	uint8_t buf2[100];
	  	int TxBufferlen,TxBufferlen1,TxBufferlen2;
	  	uint64_t timer_start;
	  	uint64_t timer_end,timer_end2;
	  	long long SysTickCnt_ms;
	  	long long SysTickCnt_start, SysTickCnt_end;
   													////
	  	/*
	  	////sine_model
	  	for(int i=0; i<5; i++)
	  	{
			uint64_t TxBufferlen1=0;
			uint64_t buf1[200];
			model = nnom_model_create();
			pre = prediction_create(model, nnom_output_data, sizeof(nnom_output_data), 4);
			uint64_t true_label[400];
			for(int j=0; j<400; j++)
			{
				memcpy(true_label, sine_input_data, 400);
				prediction_run(pre, true_label[j], &label, &prob);
				TxBufferlen1 = sprintf(buf1,"Pre_Label : %d, Pre_accuracy : %f\n",label,prob);
				HAL_UART_Transmit(&huart1, buf1, TxBufferlen1, 100);
			}
	  	}
	  	*/

 /* 	  												//////
	  	model = nnom_model_create();				// create NNoM model
	  	  	pre = prediction_create(model, nnom_output_data, sizeof(nnom_output_data), 4); // mnist, 10 classes, get top-4
	  	  	//model_set_callback(model, callback);

	  		// now takes label and data from the file and data
	  	  	for(uint64_t seek=0; seek < size;)
	  	  	{
	  	  		// labels

	  	  		uint8_t true_label[128];
	  	  		memcpy(true_label, input_data_third + seek, 128);
	  	  		seek += 128;
	  	  		// data
	  	  		SysTickCnt_start = SysTickCnt;
	  	  		for(uint64_t i=0; i < 10; i++)
	  	  		{

	  	  			//timer_start = HAL_TIM_Base_Start(&htim6);
	  	  			timer_start = __HAL_TIM_GET_COUNTER(&htim6);
	  	  			if(seek >= size)
	  	  				break;

	  	  			memcpy(nnom_input_data, input_data_third + seek, sizeof(nnom_input_data));

	  	  			seek += sizeof(nnom_input_data);

	  	  			//nnom_predict(model, &label, &prob);				// this will work independently
	  	  			prediction_run(pre, true_label[i], &label, &prob);  // this provide more infor but requires prediction API

	  	  			// save results
	  	  			//fprintf(fp, "%d,%f\n", label, prob);
	  	  			//timer_end = HAL_GetTick();
	  	  			timer_end = __HAL_TIM_GET_COUNTER(&htim6) - timer_start;

	  	  			TxBufferlen1 = sprintf(buf1,"Pre_Label : %d, Pre_accuracy : %f, us : %u \n",label,prob, timer_end);
	  	  			HAL_UART_Transmit(&huart1, buf1, TxBufferlen1, 100);
	  	  		 //HAL_UART_Transmit(&huart1, "111111111111", 100, 1000);
	  	  		//printf("GPIO_PIN_15 = %d, SysTick = %ld\r\n", HAL_GPIO_ReadPin(GPIOD, GPIO_PIN_15), HAL_GetTick());
	  	  		}
	  	  		TxBufferlen = sprintf(buf,"Processing %d%%\n", (uint32_t)(seek * 100 / size));
	  	  		//HAL_UART_Transmit(&huart1, "111111111111", 100, 1000);
	  	  		HAL_UART_Transmit(&huart1, buf, TxBufferlen, 1000);
	  	  	}
	  	  	prediction_matrix(pre);
	  	 // 	model_stat(pre);
	  	  //HAL_UART_Transmit(&huart1, "111111111111", 100, 1000);
  	 }

  	  ////
  //}

  	/*
  	if(f_mount(&SDFatFS, (TCHAR const*)SDPath, 0) != FR_OK)
  	  	{
  	  		Error_Handler();
  	  		HAL_UART_Transmit(&huart1, "1111111111", 100, 100);
  	  	}
  	  	else
  	  	{
  	  		if(f_mkfs((TCHAR const*)SDPath, FM_ANY, 0, rtext, sizeof(rtext)) != FR_OK)
  	  	    {
  	  			Error_Handler();
  	  		HAL_UART_Transmit(&huart1, "2222222222", 100, 100);
  	  	    }
  	  		else
  	  		{
  	  			//Open file for writing (Create)
  	  			if(f_open(&SDFile, "STM32.TXT", FA_CREATE_ALWAYS | FA_WRITE) != FR_OK)
  	  			{
  	  				Error_Handler();
  	  			HAL_UART_Transmit(&huart1, "333333333", 100, 100);
  	  			}
  	  			else
  	  			{

  	  				//Write to the text file
  	  				res = f_write(&SDFile, wtext, strlen((char *)wtext), (void *)&byteswritten);
  	  				if((byteswritten == 0) || (res != FR_OK))
  	  				{
  	  					Error_Handler();
  	  				HAL_UART_Transmit(&huart1, "44444444444444", 100, 100);
  	  				}
  	  				else
  	  				{

  	  					f_close(&SDFile);
  	  				HAL_UART_Transmit(&huart1, "55555555555555", 100, 100);
  	  				}
  	  			}
  	  		}
  	  	HAL_UART_Transmit(&huart1, "666666666666666", 100, 100);
  	  	}
  	  	f_mount(&SDFatFS, (TCHAR const*)NULL, 0);
  	  	HAL_UART_Transmit(&huart1, "7777777777777", 100, 100);
		*/

  /* USER CODE END 3 */
}

void SystemClock_Config(void)
{
  RCC_OscInitTypeDef RCC_OscInitStruct = {0};
  RCC_ClkInitTypeDef RCC_ClkInitStruct = {0};

  /** Configure the main internal regulator output voltage
  */
  if (HAL_PWREx_ControlVoltageScaling(PWR_REGULATOR_VOLTAGE_SCALE1) != HAL_OK)
  {
    Error_Handler();
  }

  /** Initializes the RCC Oscillators according to the specified parameters
  * in the RCC_OscInitTypeDef structure.
  */
  RCC_OscInitStruct.OscillatorType = RCC_OSCILLATORTYPE_LSE|RCC_OSCILLATORTYPE_MSI;
  RCC_OscInitStruct.LSEState = RCC_LSE_BYPASS;
  RCC_OscInitStruct.MSIState = RCC_MSI_ON;
  RCC_OscInitStruct.MSICalibrationValue = 0;
  RCC_OscInitStruct.MSIClockRange = RCC_MSIRANGE_6;
  RCC_OscInitStruct.PLL.PLLState = RCC_PLL_ON;
  RCC_OscInitStruct.PLL.PLLSource = RCC_PLLSOURCE_MSI;
  RCC_OscInitStruct.PLL.PLLM = 1;
  RCC_OscInitStruct.PLL.PLLN = 40;
  RCC_OscInitStruct.PLL.PLLP = RCC_PLLP_DIV2;
  RCC_OscInitStruct.PLL.PLLQ = RCC_PLLQ_DIV2;
  RCC_OscInitStruct.PLL.PLLR = RCC_PLLR_DIV2;
  if (HAL_RCC_OscConfig(&RCC_OscInitStruct) != HAL_OK)
  {
    Error_Handler();
  }

  /** Initializes the CPU, AHB and APB buses clocks
  */
  RCC_ClkInitStruct.ClockType = RCC_CLOCKTYPE_HCLK|RCC_CLOCKTYPE_SYSCLK
                              |RCC_CLOCKTYPE_PCLK1|RCC_CLOCKTYPE_PCLK2;
  RCC_ClkInitStruct.SYSCLKSource = RCC_SYSCLKSOURCE_PLLCLK;
  RCC_ClkInitStruct.AHBCLKDivider = RCC_SYSCLK_DIV1;
  RCC_ClkInitStruct.APB1CLKDivider = RCC_HCLK_DIV1;
  RCC_ClkInitStruct.APB2CLKDivider = RCC_HCLK_DIV1;

  if (HAL_RCC_ClockConfig(&RCC_ClkInitStruct, FLASH_LATENCY_4) != HAL_OK)
  {
    Error_Handler();
  }

  /** Enable MSI Auto calibration
  */
  HAL_RCCEx_EnableMSIPLLMode();
}

void PeriphCommonClock_Config(void)
{
  RCC_PeriphCLKInitTypeDef PeriphClkInit = {0};

  /** Initializes the peripherals clock
  */
  PeriphClkInit.PeriphClockSelection = RCC_PERIPHCLK_SAI1|RCC_PERIPHCLK_USB
                              |RCC_PERIPHCLK_SDMMC1|RCC_PERIPHCLK_ADC;
  PeriphClkInit.Sai1ClockSelection = RCC_SAI1CLKSOURCE_PLLSAI1;
  PeriphClkInit.AdcClockSelection = RCC_ADCCLKSOURCE_PLLSAI1;
  PeriphClkInit.UsbClockSelection = RCC_USBCLKSOURCE_PLLSAI1;
  PeriphClkInit.Sdmmc1ClockSelection = RCC_SDMMC1CLKSOURCE_PLLSAI1;
  PeriphClkInit.PLLSAI1.PLLSAI1Source = RCC_PLLSOURCE_MSI;
  PeriphClkInit.PLLSAI1.PLLSAI1M = 1;
  PeriphClkInit.PLLSAI1.PLLSAI1N = 24;
  PeriphClkInit.PLLSAI1.PLLSAI1P = RCC_PLLP_DIV2;
  PeriphClkInit.PLLSAI1.PLLSAI1Q = RCC_PLLQ_DIV2;
  PeriphClkInit.PLLSAI1.PLLSAI1R = RCC_PLLR_DIV2;
  PeriphClkInit.PLLSAI1.PLLSAI1ClockOut = RCC_PLLSAI1_SAI1CLK|RCC_PLLSAI1_48M2CLK
                              |RCC_PLLSAI1_ADC1CLK;
  if (HAL_RCCEx_PeriphCLKConfig(&PeriphClkInit) != HAL_OK)
  {
    Error_Handler();
  }
}

static void MX_ADC1_Init(void)
{

  ADC_MultiModeTypeDef multimode = {0};
  ADC_ChannelConfTypeDef sConfig = {0};

  /** Common config
  */
  hadc1.Instance = ADC1;
  hadc1.Init.ClockPrescaler = ADC_CLOCK_ASYNC_DIV1;
  hadc1.Init.Resolution = ADC_RESOLUTION_12B;
  hadc1.Init.DataAlign = ADC_DATAALIGN_RIGHT;
  hadc1.Init.ScanConvMode = ADC_SCAN_DISABLE;
  hadc1.Init.EOCSelection = ADC_EOC_SINGLE_CONV;
  hadc1.Init.LowPowerAutoWait = DISABLE;
  hadc1.Init.ContinuousConvMode = DISABLE;
  hadc1.Init.NbrOfConversion = 1;
  hadc1.Init.DiscontinuousConvMode = DISABLE;
  hadc1.Init.ExternalTrigConv = ADC_SOFTWARE_START;
  hadc1.Init.ExternalTrigConvEdge = ADC_EXTERNALTRIGCONVEDGE_NONE;
  hadc1.Init.DMAContinuousRequests = DISABLE;
  hadc1.Init.Overrun = ADC_OVR_DATA_PRESERVED;
  hadc1.Init.OversamplingMode = DISABLE;
  if (HAL_ADC_Init(&hadc1) != HAL_OK)
  {
    Error_Handler();
  }

  /** Configure the ADC multi-mode
  */
  multimode.Mode = ADC_MODE_INDEPENDENT;
  if (HAL_ADCEx_MultiModeConfigChannel(&hadc1, &multimode) != HAL_OK)
  {
    Error_Handler();
  }

  /** Configure Regular Channel
  */
  sConfig.Channel = ADC_CHANNEL_13;
  sConfig.Rank = ADC_REGULAR_RANK_1;
  sConfig.SamplingTime = ADC_SAMPLETIME_2CYCLES_5;
  sConfig.SingleDiff = ADC_SINGLE_ENDED;
  sConfig.OffsetNumber = ADC_OFFSET_NONE;
  sConfig.Offset = 0;
  if (HAL_ADC_ConfigChannel(&hadc1, &sConfig) != HAL_OK)
  {
    Error_Handler();
  }

}

static void MX_ADC3_Init(void)
{

  ADC_ChannelConfTypeDef sConfig = {0};

  /** Common config
  */
  hadc3.Instance = ADC3;
  hadc3.Init.ClockPrescaler = ADC_CLOCK_ASYNC_DIV1;
  hadc3.Init.Resolution = ADC_RESOLUTION_12B;
  hadc3.Init.DataAlign = ADC_DATAALIGN_RIGHT;
  hadc3.Init.ScanConvMode = ADC_SCAN_DISABLE;
  hadc3.Init.EOCSelection = ADC_EOC_SINGLE_CONV;
  hadc3.Init.LowPowerAutoWait = DISABLE;
  hadc3.Init.ContinuousConvMode = DISABLE;
  hadc3.Init.NbrOfConversion = 1;
  hadc3.Init.DiscontinuousConvMode = DISABLE;
  hadc3.Init.ExternalTrigConv = ADC_SOFTWARE_START;
  hadc3.Init.ExternalTrigConvEdge = ADC_EXTERNALTRIGCONVEDGE_NONE;
  hadc3.Init.DMAContinuousRequests = DISABLE;
  hadc3.Init.Overrun = ADC_OVR_DATA_PRESERVED;
  hadc3.Init.OversamplingMode = DISABLE;
  if (HAL_ADC_Init(&hadc3) != HAL_OK)
  {
    Error_Handler();
  }

  /** Configure Regular Channel
  */
  sConfig.Channel = ADC_CHANNEL_13;
  sConfig.Rank = ADC_REGULAR_RANK_1;
  sConfig.SamplingTime = ADC_SAMPLETIME_2CYCLES_5;
  sConfig.SingleDiff = ADC_SINGLE_ENDED;
  sConfig.OffsetNumber = ADC_OFFSET_NONE;
  sConfig.Offset = 0;
  if (HAL_ADC_ConfigChannel(&hadc3, &sConfig) != HAL_OK)
  {
    Error_Handler();
  }

}

static void MX_DCMI_Init(void)
{

  hdcmi.Instance = DCMI;
  hdcmi.Init.SynchroMode = DCMI_SYNCHRO_HARDWARE;
  hdcmi.Init.PCKPolarity = DCMI_PCKPOLARITY_FALLING;
  hdcmi.Init.VSPolarity = DCMI_VSPOLARITY_LOW;
  hdcmi.Init.HSPolarity = DCMI_HSPOLARITY_LOW;
  hdcmi.Init.CaptureRate = DCMI_CR_ALL_FRAME;
  hdcmi.Init.ExtendedDataMode = DCMI_EXTEND_DATA_8B;
  hdcmi.Init.JPEGMode = DCMI_JPEG_DISABLE;
  hdcmi.Init.ByteSelectMode = DCMI_BSM_ALL;
  hdcmi.Init.ByteSelectStart = DCMI_OEBS_ODD;
  hdcmi.Init.LineSelectMode = DCMI_LSM_ALL;
  hdcmi.Init.LineSelectStart = DCMI_OELS_ODD;
  if (HAL_DCMI_Init(&hdcmi) != HAL_OK)
  {
    Error_Handler();
  }

}

static void MX_DFSDM1_Init(void)
{

  hdfsdm1_channel1.Instance = DFSDM1_Channel1;
  hdfsdm1_channel1.Init.OutputClock.Activation = ENABLE;
  hdfsdm1_channel1.Init.OutputClock.Selection = DFSDM_CHANNEL_OUTPUT_CLOCK_SYSTEM;
  hdfsdm1_channel1.Init.OutputClock.Divider = 2;
  hdfsdm1_channel1.Init.Input.Multiplexer = DFSDM_CHANNEL_EXTERNAL_INPUTS;
  hdfsdm1_channel1.Init.Input.DataPacking = DFSDM_CHANNEL_STANDARD_MODE;
  hdfsdm1_channel1.Init.Input.Pins = DFSDM_CHANNEL_SAME_CHANNEL_PINS;
  hdfsdm1_channel1.Init.SerialInterface.Type = DFSDM_CHANNEL_SPI_RISING;
  hdfsdm1_channel1.Init.SerialInterface.SpiClock = DFSDM_CHANNEL_SPI_CLOCK_INTERNAL;
  hdfsdm1_channel1.Init.Awd.FilterOrder = DFSDM_CHANNEL_FASTSINC_ORDER;
  hdfsdm1_channel1.Init.Awd.Oversampling = 1;
  hdfsdm1_channel1.Init.Offset = 0;
  hdfsdm1_channel1.Init.RightBitShift = 0x00;
  if (HAL_DFSDM_ChannelInit(&hdfsdm1_channel1) != HAL_OK)
  {
    Error_Handler();
  }
  hdfsdm1_channel2.Instance = DFSDM1_Channel2;
  hdfsdm1_channel2.Init.OutputClock.Activation = ENABLE;
  hdfsdm1_channel2.Init.OutputClock.Selection = DFSDM_CHANNEL_OUTPUT_CLOCK_SYSTEM;
  hdfsdm1_channel2.Init.OutputClock.Divider = 2;
  hdfsdm1_channel2.Init.Input.Multiplexer = DFSDM_CHANNEL_EXTERNAL_INPUTS;
  hdfsdm1_channel2.Init.Input.DataPacking = DFSDM_CHANNEL_STANDARD_MODE;
  hdfsdm1_channel2.Init.Input.Pins = DFSDM_CHANNEL_FOLLOWING_CHANNEL_PINS;
  hdfsdm1_channel2.Init.SerialInterface.Type = DFSDM_CHANNEL_SPI_RISING;
  hdfsdm1_channel2.Init.SerialInterface.SpiClock = DFSDM_CHANNEL_SPI_CLOCK_INTERNAL;
  hdfsdm1_channel2.Init.Awd.FilterOrder = DFSDM_CHANNEL_FASTSINC_ORDER;
  hdfsdm1_channel2.Init.Awd.Oversampling = 1;
  hdfsdm1_channel2.Init.Offset = 0;
  hdfsdm1_channel2.Init.RightBitShift = 0x00;
  if (HAL_DFSDM_ChannelInit(&hdfsdm1_channel2) != HAL_OK)
  {
    Error_Handler();
  }

}

static void MX_SAI1_Init(void)
{

  hsai_BlockA1.Instance = SAI1_Block_A;
  hsai_BlockA1.Init.Protocol = SAI_FREE_PROTOCOL;
  hsai_BlockA1.Init.AudioMode = SAI_MODEMASTER_TX;
  hsai_BlockA1.Init.DataSize = SAI_DATASIZE_8;
  hsai_BlockA1.Init.FirstBit = SAI_FIRSTBIT_MSB;
  hsai_BlockA1.Init.ClockStrobing = SAI_CLOCKSTROBING_FALLINGEDGE;
  hsai_BlockA1.Init.Synchro = SAI_ASYNCHRONOUS;
  hsai_BlockA1.Init.OutputDrive = SAI_OUTPUTDRIVE_DISABLE;
  hsai_BlockA1.Init.NoDivider = SAI_MASTERDIVIDER_ENABLE;
  hsai_BlockA1.Init.FIFOThreshold = SAI_FIFOTHRESHOLD_EMPTY;
  hsai_BlockA1.Init.AudioFrequency = SAI_AUDIO_FREQUENCY_192K;
  hsai_BlockA1.Init.SynchroExt = SAI_SYNCEXT_DISABLE;
  hsai_BlockA1.Init.MonoStereoMode = SAI_STEREOMODE;
  hsai_BlockA1.Init.CompandingMode = SAI_NOCOMPANDING;
  hsai_BlockA1.Init.TriState = SAI_OUTPUT_NOTRELEASED;
  hsai_BlockA1.FrameInit.FrameLength = 8;
  hsai_BlockA1.FrameInit.ActiveFrameLength = 1;
  hsai_BlockA1.FrameInit.FSDefinition = SAI_FS_STARTFRAME;
  hsai_BlockA1.FrameInit.FSPolarity = SAI_FS_ACTIVE_LOW;
  hsai_BlockA1.FrameInit.FSOffset = SAI_FS_FIRSTBIT;
  hsai_BlockA1.SlotInit.FirstBitOffset = 0;
  hsai_BlockA1.SlotInit.SlotSize = SAI_SLOTSIZE_DATASIZE;
  hsai_BlockA1.SlotInit.SlotNumber = 1;
  hsai_BlockA1.SlotInit.SlotActive = 0x00000000;
  if (HAL_SAI_Init(&hsai_BlockA1) != HAL_OK)
  {
    Error_Handler();
  }
  hsai_BlockB1.Instance = SAI1_Block_B;
  hsai_BlockB1.Init.Protocol = SAI_FREE_PROTOCOL;
  hsai_BlockB1.Init.AudioMode = SAI_MODESLAVE_RX;
  hsai_BlockB1.Init.DataSize = SAI_DATASIZE_8;
  hsai_BlockB1.Init.FirstBit = SAI_FIRSTBIT_MSB;
  hsai_BlockB1.Init.ClockStrobing = SAI_CLOCKSTROBING_FALLINGEDGE;
  hsai_BlockB1.Init.Synchro = SAI_SYNCHRONOUS;
  hsai_BlockB1.Init.OutputDrive = SAI_OUTPUTDRIVE_DISABLE;
  hsai_BlockB1.Init.FIFOThreshold = SAI_FIFOTHRESHOLD_EMPTY;
  hsai_BlockB1.Init.SynchroExt = SAI_SYNCEXT_DISABLE;
  hsai_BlockB1.Init.MonoStereoMode = SAI_STEREOMODE;
  hsai_BlockB1.Init.CompandingMode = SAI_NOCOMPANDING;
  hsai_BlockB1.Init.TriState = SAI_OUTPUT_NOTRELEASED;
  hsai_BlockB1.FrameInit.FrameLength = 8;
  hsai_BlockB1.FrameInit.ActiveFrameLength = 1;
  hsai_BlockB1.FrameInit.FSDefinition = SAI_FS_STARTFRAME;
  hsai_BlockB1.FrameInit.FSPolarity = SAI_FS_ACTIVE_LOW;
  hsai_BlockB1.FrameInit.FSOffset = SAI_FS_FIRSTBIT;
  hsai_BlockB1.SlotInit.FirstBitOffset = 0;
  hsai_BlockB1.SlotInit.SlotSize = SAI_SLOTSIZE_DATASIZE;
  hsai_BlockB1.SlotInit.SlotNumber = 1;
  hsai_BlockB1.SlotInit.SlotActive = 0x00000000;
  if (HAL_SAI_Init(&hsai_BlockB1) != HAL_OK)
  {
    Error_Handler();
  }

}

static void MX_SDMMC1_SD_Init(void)
{

  hsd1.Instance = SDMMC1;
  hsd1.Init.ClockEdge = SDMMC_CLOCK_EDGE_RISING;
  hsd1.Init.ClockBypass = SDMMC_CLOCK_BYPASS_DISABLE;
  hsd1.Init.ClockPowerSave = SDMMC_CLOCK_POWER_SAVE_DISABLE;
  hsd1.Init.BusWide = SDMMC_BUS_WIDE_4B;
  hsd1.Init.HardwareFlowControl = SDMMC_HARDWARE_FLOW_CONTROL_DISABLE;
  hsd1.Init.ClockDiv = 0;

}

static void MX_SPI2_Init(void)
{

  /* SPI2 parameter configuration*/
  hspi2.Instance = SPI2;
  hspi2.Init.Mode = SPI_MODE_MASTER;
  hspi2.Init.Direction = SPI_DIRECTION_2LINES;
  hspi2.Init.DataSize = SPI_DATASIZE_4BIT;
  hspi2.Init.CLKPolarity = SPI_POLARITY_LOW;
  hspi2.Init.CLKPhase = SPI_PHASE_1EDGE;
  hspi2.Init.NSS = SPI_NSS_SOFT;
  hspi2.Init.BaudRatePrescaler = SPI_BAUDRATEPRESCALER_2;
  hspi2.Init.FirstBit = SPI_FIRSTBIT_MSB;
  hspi2.Init.TIMode = SPI_TIMODE_DISABLE;
  hspi2.Init.CRCCalculation = SPI_CRCCALCULATION_DISABLE;
  hspi2.Init.CRCPolynomial = 7;
  hspi2.Init.CRCLength = SPI_CRC_LENGTH_DATASIZE;
  hspi2.Init.NSSPMode = SPI_NSS_PULSE_ENABLE;
  if (HAL_SPI_Init(&hspi2) != HAL_OK)
  {
    Error_Handler();
  }

}

static void MX_TIM5_Init(void)
{

  TIM_ClockConfigTypeDef sClockSourceConfig = {0};
  TIM_MasterConfigTypeDef sMasterConfig = {0};

  htim5.Instance = TIM5;
  htim5.Init.Prescaler = 1-1;
  htim5.Init.CounterMode = TIM_COUNTERMODE_UP;
  htim5.Init.Period = 0xffffffff-1;
  htim5.Init.ClockDivision = TIM_CLOCKDIVISION_DIV1;
  htim5.Init.AutoReloadPreload = TIM_AUTORELOAD_PRELOAD_DISABLE;
  if (HAL_TIM_Base_Init(&htim5) != HAL_OK)
  {
    Error_Handler();
  }
  sClockSourceConfig.ClockSource = TIM_CLOCKSOURCE_INTERNAL;
  if (HAL_TIM_ConfigClockSource(&htim5, &sClockSourceConfig) != HAL_OK)
  {
    Error_Handler();
  }
  sMasterConfig.MasterOutputTrigger = TIM_TRGO_RESET;
  sMasterConfig.MasterSlaveMode = TIM_MASTERSLAVEMODE_DISABLE;
  if (HAL_TIMEx_MasterConfigSynchronization(&htim5, &sMasterConfig) != HAL_OK)
  {
    Error_Handler();
  }

}

static void MX_TIM6_Init(void)
{

  TIM_MasterConfigTypeDef sMasterConfig = {0};

  htim6.Instance = TIM6;
  htim6.Init.Prescaler = 80-1;
  htim6.Init.CounterMode = TIM_COUNTERMODE_UP;
  htim6.Init.Period = 65536-1;
  htim6.Init.AutoReloadPreload = TIM_AUTORELOAD_PRELOAD_DISABLE;
  if (HAL_TIM_Base_Init(&htim6) != HAL_OK)
  {
    Error_Handler();
  }
  sMasterConfig.MasterOutputTrigger = TIM_TRGO_RESET;
  sMasterConfig.MasterSlaveMode = TIM_MASTERSLAVEMODE_DISABLE;
  if (HAL_TIMEx_MasterConfigSynchronization(&htim6, &sMasterConfig) != HAL_OK)
  {
    Error_Handler();
  }

}

static void MX_USART1_UART_Init(void)
{

  huart1.Instance = USART1;
  huart1.Init.BaudRate = 115200;
  huart1.Init.WordLength = UART_WORDLENGTH_8B;
  huart1.Init.StopBits = UART_STOPBITS_1;
  huart1.Init.Parity = UART_PARITY_NONE;
  huart1.Init.Mode = UART_MODE_TX_RX;
  huart1.Init.HwFlowCtl = UART_HWCONTROL_NONE;
  huart1.Init.OverSampling = UART_OVERSAMPLING_16;
  huart1.Init.OneBitSampling = UART_ONE_BIT_SAMPLE_DISABLE;
  huart1.AdvancedInit.AdvFeatureInit = UART_ADVFEATURE_NO_INIT;
  if (HAL_UART_Init(&huart1) != HAL_OK)
  {
    Error_Handler();
  }

}

static void MX_DMA_Init(void)
{

  /* DMA controller clock enable */
  __HAL_RCC_DMA2_CLK_ENABLE();

  /* DMA interrupt init */
  /* DMA2_Channel4_IRQn interrupt configuration */
  HAL_NVIC_SetPriority(DMA2_Channel4_IRQn, 5, 0);
  HAL_NVIC_EnableIRQ(DMA2_Channel4_IRQn);
  /* DMA2_Channel5_IRQn interrupt configuration */
  HAL_NVIC_SetPriority(DMA2_Channel5_IRQn, 5, 0);
  HAL_NVIC_EnableIRQ(DMA2_Channel5_IRQn);

}

/* FMC initialization function */
static void MX_FMC_Init(void)
{

  FMC_NORSRAM_TimingTypeDef Timing = {0};

  /** Perform the SRAM1 memory initialization sequence
  */
  hsram1.Instance = FMC_NORSRAM_DEVICE;
  hsram1.Extended = FMC_NORSRAM_EXTENDED_DEVICE;
  /* hsram1.Init */
  hsram1.Init.NSBank = FMC_NORSRAM_BANK2;
  hsram1.Init.DataAddressMux = FMC_DATA_ADDRESS_MUX_DISABLE;
  hsram1.Init.MemoryType = FMC_MEMORY_TYPE_SRAM;
  hsram1.Init.MemoryDataWidth = FMC_NORSRAM_MEM_BUS_WIDTH_16;
  hsram1.Init.BurstAccessMode = FMC_BURST_ACCESS_MODE_DISABLE;
  hsram1.Init.WaitSignalPolarity = FMC_WAIT_SIGNAL_POLARITY_LOW;
  hsram1.Init.WaitSignalActive = FMC_WAIT_TIMING_BEFORE_WS;
  hsram1.Init.WriteOperation = FMC_WRITE_OPERATION_DISABLE;
  hsram1.Init.WaitSignal = FMC_WAIT_SIGNAL_DISABLE;
  hsram1.Init.ExtendedMode = FMC_EXTENDED_MODE_DISABLE;
  hsram1.Init.AsynchronousWait = FMC_ASYNCHRONOUS_WAIT_DISABLE;
  hsram1.Init.WriteBurst = FMC_WRITE_BURST_DISABLE;
  hsram1.Init.ContinuousClock = FMC_CONTINUOUS_CLOCK_SYNC_ONLY;
  hsram1.Init.WriteFifo = FMC_WRITE_FIFO_ENABLE;
  hsram1.Init.PageSize = FMC_PAGE_SIZE_NONE;
  /* Timing */
  Timing.AddressSetupTime = 15;
  Timing.AddressHoldTime = 15;
  Timing.DataSetupTime = 255;
  Timing.BusTurnAroundDuration = 15;
  Timing.CLKDivision = 16;
  Timing.DataLatency = 17;
  Timing.AccessMode = FMC_ACCESS_MODE_A;
  /* ExtTiming */

  if (HAL_SRAM_Init(&hsram1, &Timing, NULL) != HAL_OK)
  {
    Error_Handler( );
  }

  /** Perform the SRAM2 memory initialization sequence
  */
  hsram2.Instance = FMC_NORSRAM_DEVICE;
  hsram2.Extended = FMC_NORSRAM_EXTENDED_DEVICE;
  /* hsram2.Init */
  hsram2.Init.NSBank = FMC_NORSRAM_BANK1;
  hsram2.Init.DataAddressMux = FMC_DATA_ADDRESS_MUX_DISABLE;
  hsram2.Init.MemoryType = FMC_MEMORY_TYPE_SRAM;
  hsram2.Init.MemoryDataWidth = FMC_NORSRAM_MEM_BUS_WIDTH_16;
  hsram2.Init.BurstAccessMode = FMC_BURST_ACCESS_MODE_DISABLE;
  hsram2.Init.WaitSignalPolarity = FMC_WAIT_SIGNAL_POLARITY_LOW;
  hsram2.Init.WaitSignalActive = FMC_WAIT_TIMING_BEFORE_WS;
  hsram2.Init.WriteOperation = FMC_WRITE_OPERATION_ENABLE;
  hsram2.Init.WaitSignal = FMC_WAIT_SIGNAL_DISABLE;
  hsram2.Init.ExtendedMode = FMC_EXTENDED_MODE_DISABLE;
  hsram2.Init.AsynchronousWait = FMC_ASYNCHRONOUS_WAIT_DISABLE;
  hsram2.Init.WriteBurst = FMC_WRITE_BURST_DISABLE;
  hsram2.Init.ContinuousClock = FMC_CONTINUOUS_CLOCK_SYNC_ONLY;
  hsram2.Init.WriteFifo = FMC_WRITE_FIFO_ENABLE;
  hsram2.Init.PageSize = FMC_PAGE_SIZE_NONE;
  /* Timing */
  Timing.AddressSetupTime = 15;
  Timing.AddressHoldTime = 15;
  Timing.DataSetupTime = 255;
  Timing.BusTurnAroundDuration = 15;
  Timing.CLKDivision = 16;
  Timing.DataLatency = 17;
  Timing.AccessMode = FMC_ACCESS_MODE_A;
  /* ExtTiming */

  if (HAL_SRAM_Init(&hsram2, &Timing, NULL) != HAL_OK)
  {
    Error_Handler( );
  }

}

static void MX_GPIO_Init(void)
{
  GPIO_InitTypeDef GPIO_InitStruct = {0};

  /* GPIO Ports Clock Enable */
  __HAL_RCC_GPIOI_CLK_ENABLE();
  __HAL_RCC_GPIOH_CLK_ENABLE();
  __HAL_RCC_GPIOE_CLK_ENABLE();
  __HAL_RCC_GPIOB_CLK_ENABLE();
  __HAL_RCC_GPIOA_CLK_ENABLE();
  __HAL_RCC_GPIOG_CLK_ENABLE();
  HAL_PWREx_EnableVddIO2();
  __HAL_RCC_GPIOD_CLK_ENABLE();
  __HAL_RCC_GPIOC_CLK_ENABLE();
  __HAL_RCC_GPIOF_CLK_ENABLE();

  /*Configure GPIO pin Output Level */
  HAL_GPIO_WritePin(LCD_BL_GPIO_Port, LCD_BL_Pin, GPIO_PIN_RESET);

  /*Configure GPIO pin Output Level */
  HAL_GPIO_WritePin(GPIOH, MFX_WAKEUP_Pin|LCD_PWR_ON_Pin|MIC_VDD_Pin, GPIO_PIN_RESET);

  /*Configure GPIO pin Output Level */
  HAL_GPIO_WritePin(Audio_RST_GPIO_Port, Audio_RST_Pin, GPIO_PIN_RESET);

  /*Configure GPIO pin Output Level */
  HAL_GPIO_WritePin(LED1_GPIO_Port, LED1_Pin, GPIO_PIN_RESET);

  /*Configure GPIO pins : JOY_DOWN_Pin JOY_LEFT_Pin JOY_UP_Pin */
  GPIO_InitStruct.Pin = JOY_DOWN_Pin|JOY_LEFT_Pin|JOY_UP_Pin;
  GPIO_InitStruct.Mode = GPIO_MODE_INPUT;
  GPIO_InitStruct.Pull = GPIO_PULLDOWN;
  HAL_GPIO_Init(GPIOI, &GPIO_InitStruct);

  /*Configure GPIO pin : STMOD_INT_Pin */
  GPIO_InitStruct.Pin = STMOD_INT_Pin;
  GPIO_InitStruct.Mode = GPIO_MODE_IT_RISING;
  GPIO_InitStruct.Pull = GPIO_NOPULL;
  HAL_GPIO_Init(STMOD_INT_GPIO_Port, &GPIO_InitStruct);

  /*Configure GPIO pins : ARD_D12_Pin ARD_D11_Pin */
  GPIO_InitStruct.Pin = ARD_D12_Pin|ARD_D11_Pin;
  GPIO_InitStruct.Mode = GPIO_MODE_AF_PP;
  GPIO_InitStruct.Pull = GPIO_NOPULL;
  GPIO_InitStruct.Speed = GPIO_SPEED_FREQ_VERY_HIGH;
  GPIO_InitStruct.Alternate = GPIO_AF5_SPI1;
  HAL_GPIO_Init(GPIOB, &GPIO_InitStruct);

  /*Configure GPIO pins : ARD_D10_Pin ARD_D13_Pin */
  GPIO_InitStruct.Pin = ARD_D10_Pin|ARD_D13_Pin;
  GPIO_InitStruct.Mode = GPIO_MODE_AF_PP;
  GPIO_InitStruct.Pull = GPIO_NOPULL;
  GPIO_InitStruct.Speed = GPIO_SPEED_FREQ_VERY_HIGH;
  GPIO_InitStruct.Alternate = GPIO_AF5_SPI1;
  HAL_GPIO_Init(GPIOA, &GPIO_InitStruct);

  /*Configure GPIO pin : LCD_BL_Pin */
  GPIO_InitStruct.Pin = LCD_BL_Pin;
  GPIO_InitStruct.Mode = GPIO_MODE_OUTPUT_PP;
  GPIO_InitStruct.Pull = GPIO_NOPULL;
  GPIO_InitStruct.Speed = GPIO_SPEED_FREQ_LOW;
  HAL_GPIO_Init(LCD_BL_GPIO_Port, &GPIO_InitStruct);

  /*Configure GPIO pin : ARD_D6_Pin */
  GPIO_InitStruct.Pin = ARD_D6_Pin;
  GPIO_InitStruct.Mode = GPIO_MODE_AF_PP;
  GPIO_InitStruct.Pull = GPIO_NOPULL;
  GPIO_InitStruct.Speed = GPIO_SPEED_FREQ_LOW;
  GPIO_InitStruct.Alternate = GPIO_AF3_TIM8;
  HAL_GPIO_Init(ARD_D6_GPIO_Port, &GPIO_InitStruct);

  /*Configure GPIO pins : ARD_D3_Pin ARD_D9_Pin */
  GPIO_InitStruct.Pin = ARD_D3_Pin|ARD_D9_Pin;
  GPIO_InitStruct.Mode = GPIO_MODE_AF_PP;
  GPIO_InitStruct.Pull = GPIO_NOPULL;
  GPIO_InitStruct.Speed = GPIO_SPEED_FREQ_LOW;
  GPIO_InitStruct.Alternate = GPIO_AF3_TIM8;
  HAL_GPIO_Init(GPIOH, &GPIO_InitStruct);

  /*Configure GPIO pins : I2C1_SCL_Pin I2C1_SDA_Pin */
  GPIO_InitStruct.Pin = I2C1_SCL_Pin|I2C1_SDA_Pin;
  GPIO_InitStruct.Mode = GPIO_MODE_AF_OD;
  GPIO_InitStruct.Pull = GPIO_PULLUP;
  GPIO_InitStruct.Speed = GPIO_SPEED_FREQ_VERY_HIGH;
  GPIO_InitStruct.Alternate = GPIO_AF4_I2C1;
  HAL_GPIO_Init(GPIOB, &GPIO_InitStruct);

  /*Configure GPIO pin : ARD_D5_Pin */
  GPIO_InitStruct.Pin = ARD_D5_Pin;
  GPIO_InitStruct.Mode = GPIO_MODE_AF_PP;
  GPIO_InitStruct.Pull = GPIO_NOPULL;
  GPIO_InitStruct.Speed = GPIO_SPEED_FREQ_LOW;
  GPIO_InitStruct.Alternate = GPIO_AF2_TIM4;
  HAL_GPIO_Init(ARD_D5_GPIO_Port, &GPIO_InitStruct);

  /*Configure GPIO pin : LCD_TE_Pin */
  GPIO_InitStruct.Pin = LCD_TE_Pin;
  GPIO_InitStruct.Mode = GPIO_MODE_INPUT;
  GPIO_InitStruct.Pull = GPIO_NOPULL;
  HAL_GPIO_Init(LCD_TE_GPIO_Port, &GPIO_InitStruct);

  /*Configure GPIO pin : USART2_RX_Pin */
  GPIO_InitStruct.Pin = USART2_RX_Pin;
  GPIO_InitStruct.Mode = GPIO_MODE_AF_PP;
  GPIO_InitStruct.Pull = GPIO_NOPULL;
  GPIO_InitStruct.Speed = GPIO_SPEED_FREQ_VERY_HIGH;
  GPIO_InitStruct.Alternate = GPIO_AF7_USART2;
  HAL_GPIO_Init(USART2_RX_GPIO_Port, &GPIO_InitStruct);

  /*Configure GPIO pins : MFX_WAKEUP_Pin LCD_PWR_ON_Pin MIC_VDD_Pin */
  GPIO_InitStruct.Pin = MFX_WAKEUP_Pin|LCD_PWR_ON_Pin|MIC_VDD_Pin;
  GPIO_InitStruct.Mode = GPIO_MODE_OUTPUT_PP;
  GPIO_InitStruct.Pull = GPIO_NOPULL;
  GPIO_InitStruct.Speed = GPIO_SPEED_FREQ_LOW;
  HAL_GPIO_Init(GPIOH, &GPIO_InitStruct);

  /*Configure GPIO pin : Audio_RST_Pin */
  GPIO_InitStruct.Pin = Audio_RST_Pin;
  GPIO_InitStruct.Mode = GPIO_MODE_OUTPUT_PP;
  GPIO_InitStruct.Pull = GPIO_NOPULL;
  GPIO_InitStruct.Speed = GPIO_SPEED_FREQ_LOW;
  HAL_GPIO_Init(Audio_RST_GPIO_Port, &GPIO_InitStruct);

  /*Configure GPIO pin : CTP_INT_Pin */
  GPIO_InitStruct.Pin = CTP_INT_Pin;
  GPIO_InitStruct.Mode = GPIO_MODE_IT_RISING;
  GPIO_InitStruct.Pull = GPIO_NOPULL;
  HAL_GPIO_Init(CTP_INT_GPIO_Port, &GPIO_InitStruct);

  /*Configure GPIO pin : DCMI_CLK_Pin */
  GPIO_InitStruct.Pin = DCMI_CLK_Pin;
  GPIO_InitStruct.Mode = GPIO_MODE_AF_PP;
  GPIO_InitStruct.Pull = GPIO_NOPULL;
  GPIO_InitStruct.Speed = GPIO_SPEED_FREQ_LOW;
  GPIO_InitStruct.Alternate = GPIO_AF14_LPTIM2;
  HAL_GPIO_Init(DCMI_CLK_GPIO_Port, &GPIO_InitStruct);

  /*Configure GPIO pins : QSPI_BK1_NCS_Pin QSPI_BK1_IO1_Pin QSPI_BK1_IO0_Pin */
  GPIO_InitStruct.Pin = QSPI_BK1_NCS_Pin|QSPI_BK1_IO1_Pin|QSPI_BK1_IO0_Pin;
  GPIO_InitStruct.Mode = GPIO_MODE_AF_PP;
  GPIO_InitStruct.Pull = GPIO_NOPULL;
  GPIO_InitStruct.Speed = GPIO_SPEED_FREQ_VERY_HIGH;
  GPIO_InitStruct.Alternate = GPIO_AF10_QUADSPI;
  HAL_GPIO_Init(GPIOB, &GPIO_InitStruct);

  /*Configure GPIO pins : ARD_D0_Pin ARD_D1_Pin */
  GPIO_InitStruct.Pin = ARD_D0_Pin|ARD_D1_Pin;
  GPIO_InitStruct.Mode = GPIO_MODE_AF_PP;
  GPIO_InitStruct.Pull = GPIO_NOPULL;
  GPIO_InitStruct.Speed = GPIO_SPEED_FREQ_VERY_HIGH;
  GPIO_InitStruct.Alternate = GPIO_AF8_LPUART1;
  HAL_GPIO_Init(GPIOG, &GPIO_InitStruct);

  /*Configure GPIO pins : ARD_A5_Pin PC1 */
  GPIO_InitStruct.Pin = ARD_A5_Pin|GPIO_PIN_1;
  GPIO_InitStruct.Mode = GPIO_MODE_ANALOG;
  GPIO_InitStruct.Pull = GPIO_NOPULL;
  HAL_GPIO_Init(GPIOC, &GPIO_InitStruct);

  /*Configure GPIO pin : MFX_IRQ_OUT_Pin */
  GPIO_InitStruct.Pin = MFX_IRQ_OUT_Pin;
  GPIO_InitStruct.Mode = GPIO_MODE_IT_RISING;
  GPIO_InitStruct.Pull = GPIO_NOPULL;
  HAL_GPIO_Init(MFX_IRQ_OUT_GPIO_Port, &GPIO_InitStruct);

  /*Configure GPIO pin : I2C2_SCL_Pin */
  GPIO_InitStruct.Pin = I2C2_SCL_Pin;
  GPIO_InitStruct.Mode = GPIO_MODE_AF_OD;
  GPIO_InitStruct.Pull = GPIO_PULLUP;
  GPIO_InitStruct.Speed = GPIO_SPEED_FREQ_VERY_HIGH;
  GPIO_InitStruct.Alternate = GPIO_AF4_I2C2;
  HAL_GPIO_Init(I2C2_SCL_GPIO_Port, &GPIO_InitStruct);

  /*Configure GPIO pins : STMOD_ADC_Pin ARD_A4_Pin */
  GPIO_InitStruct.Pin = STMOD_ADC_Pin|ARD_A4_Pin;
  GPIO_InitStruct.Mode = GPIO_MODE_ANALOG;
  GPIO_InitStruct.Pull = GPIO_NOPULL;
  HAL_GPIO_Init(GPIOA, &GPIO_InitStruct);

  /*Configure GPIO pins : QSPI_BK1_IO2_Pin QSPI_CLK_Pin QSPI_BK1_IO3_Pin */
  GPIO_InitStruct.Pin = QSPI_BK1_IO2_Pin|QSPI_CLK_Pin|QSPI_BK1_IO3_Pin;
  GPIO_InitStruct.Mode = GPIO_MODE_AF_PP;
  GPIO_InitStruct.Pull = GPIO_NOPULL;
  GPIO_InitStruct.Speed = GPIO_SPEED_FREQ_VERY_HIGH;
  GPIO_InitStruct.Alternate = GPIO_AF10_QUADSPI;
  HAL_GPIO_Init(GPIOA, &GPIO_InitStruct);

  /*Configure GPIO pin : JOY_RIGHT_Pin */
  GPIO_InitStruct.Pin = JOY_RIGHT_Pin;
  GPIO_InitStruct.Mode = GPIO_MODE_INPUT;
  GPIO_InitStruct.Pull = GPIO_PULLDOWN;
  HAL_GPIO_Init(JOY_RIGHT_GPIO_Port, &GPIO_InitStruct);

  /*Configure GPIO pin : I2C2_SDA_Pin */
  GPIO_InitStruct.Pin = I2C2_SDA_Pin;
  GPIO_InitStruct.Mode = GPIO_MODE_AF_OD;
  GPIO_InitStruct.Pull = GPIO_PULLUP;
  GPIO_InitStruct.Speed = GPIO_SPEED_FREQ_VERY_HIGH;
  GPIO_InitStruct.Alternate = GPIO_AF4_I2C2;
  HAL_GPIO_Init(I2C2_SDA_GPIO_Port, &GPIO_InitStruct);

  /*Configure GPIO pin : USART2_TX_Pin */
  GPIO_InitStruct.Pin = USART2_TX_Pin;
  GPIO_InitStruct.Mode = GPIO_MODE_AF_PP;
  GPIO_InitStruct.Pull = GPIO_NOPULL;
  GPIO_InitStruct.Speed = GPIO_SPEED_FREQ_VERY_HIGH;
  GPIO_InitStruct.Alternate = GPIO_AF7_USART2;
  HAL_GPIO_Init(USART2_TX_GPIO_Port, &GPIO_InitStruct);

  /*Configure GPIO pin : STMOD_RESET_Pin */
  GPIO_InitStruct.Pin = STMOD_RESET_Pin;
  GPIO_InitStruct.Mode = GPIO_MODE_INPUT;
  GPIO_InitStruct.Pull = GPIO_NOPULL;
  HAL_GPIO_Init(STMOD_RESET_GPIO_Port, &GPIO_InitStruct);

  /*Configure GPIO pin : LED1_Pin */
  GPIO_InitStruct.Pin = LED1_Pin;
  GPIO_InitStruct.Mode = GPIO_MODE_OUTPUT_OD;
  GPIO_InitStruct.Pull = GPIO_NOPULL;
  GPIO_InitStruct.Speed = GPIO_SPEED_FREQ_LOW;
  HAL_GPIO_Init(LED1_GPIO_Port, &GPIO_InitStruct);

}

void Error_Handler(void)
{
  __disable_irq();
  while (1)
  {
  }
}
